/* Description: LIN Description file */
/* System: Superset_EVAC */
/* Variant: Superset */
/* Cluster: LIN15_BCMA */
/* Master: BCMA_LIN15_Ctrl */
/* Generated at: 2026-03-06 10:21 */

LIN_description_file;
LIN_protocol_version = "2.1";
LIN_language_version = "2.1";
LIN_speed = 19.2 kbps;

Channel_name = "";

Nodes {
  Master: BCMA, 5.000 ms, 0.500 ms;
  Slaves: ALM, ALM2, ALM3, ALM4, ALM5, ALM6, ALM7, ALM8, Virtual_EVAC, WCCM;
}

Signals {
  AmbLightBlue1: 8, 0, BCMA, ALM, ALM2, ALM3, ALM4, ALM5, ALM6, ALM7, ALM8;
  AmbLightBlue2: 8, 0, BCMA, ALM, ALM2, ALM3, ALM4, ALM5, ALM6, ALM7, ALM8;
  AmbLightBlue3: 8, 0, BCMA, ALM, ALM2, ALM3, ALM4, ALM5, ALM6, ALM7, ALM8;
  AmbLightBlue4: 8, 0, BCMA, ALM, ALM2, ALM3, ALM4, ALM5, ALM6, ALM7, ALM8;
  AmbLightBlue5: 8, 0, BCMA, ALM, ALM2, ALM3, ALM4, ALM5, ALM6, ALM7, ALM8;
  AmbLIghtFade1: 8, 0, BCMA, ALM, ALM2, ALM3, ALM4, ALM5, ALM6, ALM7, ALM8;
  AmbLIghtFade2: 8, 0, BCMA, ALM, ALM2, ALM3, ALM4, ALM5, ALM6, ALM7, ALM8;
  AmbLIghtFade3: 8, 0, BCMA, ALM, ALM2, ALM3, ALM4, ALM5, ALM6, ALM7, ALM8;
  AmbLIghtFade4: 8, 0, BCMA, ALM, ALM2, ALM3, ALM4, ALM5, ALM6, ALM7, ALM8;
  AmbLIghtFade5: 8, 0, BCMA, ALM, ALM2, ALM3, ALM4, ALM5, ALM6, ALM7, ALM8;
  AmbLightGreen1: 8, 0, BCMA, ALM, ALM2, ALM3, ALM4, ALM5, ALM6, ALM7, ALM8;
  AmbLightGreen2: 8, 0, BCMA, ALM, ALM2, ALM3, ALM4, ALM5, ALM6, ALM7, ALM8;
  AmbLightGreen3: 8, 0, BCMA, ALM, ALM2, ALM3, ALM4, ALM5, ALM6, ALM7, ALM8;
  AmbLightGreen4: 8, 0, BCMA, ALM, ALM2, ALM3, ALM4, ALM5, ALM6, ALM7, ALM8;
  AmbLightGreen5: 8, 0, BCMA, ALM, ALM2, ALM3, ALM4, ALM5, ALM6, ALM7, ALM8;
  AmbLightIntensity1: 6, 0, BCMA, ALM, ALM2, ALM3, ALM4, ALM5, ALM6, ALM7, ALM8;
  AmbLightIntensity2: 6, 0, BCMA, ALM, ALM2, ALM3, ALM4, ALM5, ALM6, ALM7, ALM8;
  AmbLightIntensity3: 6, 0, BCMA, ALM, ALM2, ALM3, ALM4, ALM5, ALM6, ALM7, ALM8;
  AmbLightIntensity4: 6, 0, BCMA, ALM, ALM2, ALM3, ALM4, ALM5, ALM6, ALM7, ALM8;
  AmbLightIntensity5: 6, 0, BCMA, ALM, ALM2, ALM3, ALM4, ALM5, ALM6, ALM7, ALM8;
  AmbLightRamp1: 8, 0, BCMA, ALM, ALM2, ALM3, ALM4, ALM5, ALM6, ALM7, ALM8;
  AmbLightRamp2: 8, 0, BCMA, ALM, ALM2, ALM3, ALM4, ALM5, ALM6, ALM7, ALM8;
  AmbLightRamp3: 8, 0, BCMA, ALM, ALM2, ALM3, ALM4, ALM5, ALM6, ALM7, ALM8;
  AmbLightRamp4: 8, 0, BCMA, ALM, ALM2, ALM3, ALM4, ALM5, ALM6, ALM7, ALM8;
  AmbLightRamp5: 8, 0, BCMA, ALM, ALM2, ALM3, ALM4, ALM5, ALM6, ALM7, ALM8;
  AmbLightRed1: 8, 0, BCMA, ALM, ALM2, ALM3, ALM4, ALM5, ALM6, ALM7, ALM8;
  AmbLightRed2: 8, 0, BCMA, ALM, ALM2, ALM3, ALM4, ALM5, ALM6, ALM7, ALM8;
  AmbLightRed3: 8, 0, BCMA, ALM, ALM2, ALM3, ALM4, ALM5, ALM6, ALM7, ALM8;
  AmbLightRed4: 8, 0, BCMA, ALM, ALM2, ALM3, ALM4, ALM5, ALM6, ALM7, ALM8;
  AmbLightRed5: 8, 0, BCMA, ALM, ALM2, ALM3, ALM4, ALM5, ALM6, ALM7, ALM8;
  AmbLightSeqfrom1: 8, 0, BCMA, ALM, ALM2, ALM3, ALM4, ALM5, ALM6, ALM7, ALM8;
  AmbLightSeqfrom2: 8, 0, BCMA, ALM, ALM2, ALM3, ALM4, ALM5, ALM6, ALM7, ALM8;
  AmbLightSeqfrom3: 8, 0, BCMA, ALM, ALM2, ALM3, ALM4, ALM5, ALM6, ALM7, ALM8;
  AmbLightSeqfrom4: 8, 0, BCMA, ALM, ALM2, ALM3, ALM4, ALM5, ALM6, ALM7, ALM8;
  AmbLightSeqfrom5: 8, 0, BCMA, ALM, ALM2, ALM3, ALM4, ALM5, ALM6, ALM7, ALM8;
  AmbLightSeqTo1: 8, 0, BCMA, ALM, ALM2, ALM3, ALM4, ALM5, ALM6, ALM7, ALM8;
  AmbLightSeqTo2: 8, 0, BCMA, ALM, ALM2, ALM3, ALM4, ALM5, ALM6, ALM7, ALM8;
  AmbLightSeqTo3: 8, 0, BCMA, ALM, ALM2, ALM3, ALM4, ALM5, ALM6, ALM7, ALM8;
  AmbLightSeqTo4: 8, 0, BCMA, ALM, ALM2, ALM3, ALM4, ALM5, ALM6, ALM7, ALM8;
  AmbLightSeqTo5: 8, 0, BCMA, ALM, ALM2, ALM3, ALM4, ALM5, ALM6, ALM7, ALM8;
  AmbLightUpdate1: 2, 0, BCMA, ALM, ALM2, ALM3, ALM4, ALM5, ALM6, ALM7, ALM8;
  AmbLightUpdate2: 2, 0, BCMA, ALM, ALM2, ALM3, ALM4, ALM5, ALM6, ALM7, ALM8;
  AmbLightUpdate3: 2, 0, BCMA, ALM, ALM2, ALM3, ALM4, ALM5, ALM6, ALM7, ALM8;
  AmbLightUpdate4: 2, 0, BCMA, ALM, ALM2, ALM3, ALM4, ALM5, ALM6, ALM7, ALM8;
  AmbLightUpdate5: 2, 0, BCMA, ALM, ALM2, ALM3, ALM4, ALM5, ALM6, ALM7, ALM8;
  BacklightIntensity: 8, 0, BCMA, WCCM;
  BacklightStatus: 1, 0, BCMA, WCCM;
  DiagMasterReqB0_L15: 8, 0, BCMA, Virtual_EVAC;
  DiagMasterReqB1_L15: 8, 0, BCMA, Virtual_EVAC;
  DiagMasterReqB2_L15: 8, 0, BCMA, Virtual_EVAC;
  DiagMasterReqB3_L15: 8, 0, BCMA, Virtual_EVAC;
  DiagMasterReqB4_L15: 8, 0, BCMA, Virtual_EVAC;
  DiagMasterReqB5_L15: 8, 0, BCMA, Virtual_EVAC;
  DiagMasterReqB6_L15: 8, 0, BCMA, Virtual_EVAC;
  DiagMasterReqB7_L15: 8, 0, BCMA, Virtual_EVAC;
  DiagSlaveRespB0_L15: 8, 0, Virtual_EVAC, BCMA;
  DiagSlaveRespB1_L15: 8, 0, Virtual_EVAC, BCMA;
  DiagSlaveRespB2_L15: 8, 0, Virtual_EVAC, BCMA;
  DiagSlaveRespB3_L15: 8, 0, Virtual_EVAC, BCMA;
  DiagSlaveRespB4_L15: 8, 0, Virtual_EVAC, BCMA;
  DiagSlaveRespB5_L15: 8, 0, Virtual_EVAC, BCMA;
  DiagSlaveRespB6_L15: 8, 0, Virtual_EVAC, BCMA;
  DiagSlaveRespB7_L15: 8, 0, Virtual_EVAC, BCMA;
  ElPowerStatus: 2, 0, BCMA, WCCM;
  LimitedPowerMode: 1, 0, BCMA, WCCM;
  PBBatVolt: 8, 140, BCMA, WCCM;
  PowerMode_LIN: 5, 0, BCMA, WCCM;
  SPBBatVolt: 8, 140, BCMA, WCCM;
  WCCMPartNo: 16, 0, WCCM, BCMA;
  WCCMPartNoBlkNo: 4, 0, WCCM, BCMA;
  WCCMSerialNo: 16, 0, WCCM, BCMA;
  WCCMSerialNoBlkNo: 3, 0, WCCM, BCMA;
  ErrRespALM: 1, 0, ALM, BCMA;
  ErrRespALM2: 1, 0, ALM2, BCMA;
  ErrRespALM3: 1, 0, ALM3, BCMA;
  ErrRespALM4: 1, 0, ALM4, BCMA;
  ErrRespALM5: 1, 0, ALM5, BCMA;
  ErrRespALM6: 1, 0, ALM6, BCMA;
  ErrRespALM7: 1, 0, ALM7, BCMA;
  ErrRespALM8: 1, 0, ALM8, BCMA;
  ErrRespWCCM: 1, 0, WCCM, BCMA;
}

Frames {
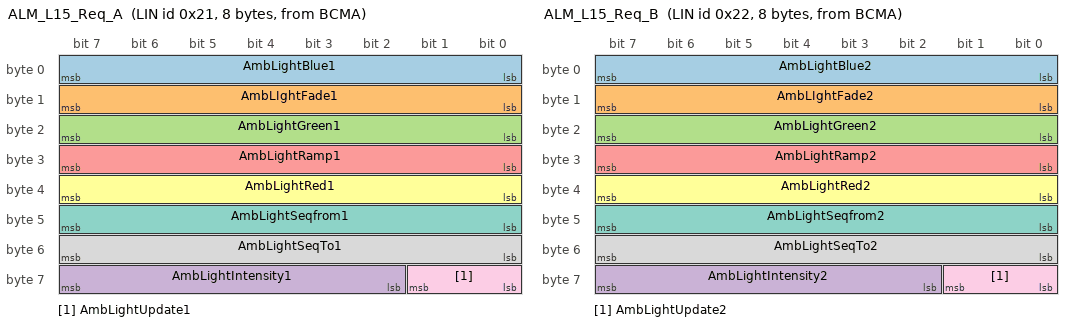
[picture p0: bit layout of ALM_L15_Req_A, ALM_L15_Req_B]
  ALM_L15_Req_A: 0x21, BCMA, 8 {
    AmbLightBlue1, 0;
    AmbLIghtFade1, 8;
    AmbLightGreen1, 16;
    AmbLightIntensity1, 58;
    AmbLightRamp1, 24;
    AmbLightRed1, 32;
    AmbLightSeqfrom1, 40;
    AmbLightSeqTo1, 48;
    AmbLightUpdate1, 56;
  }
  ALM_L15_Req_B: 0x22, BCMA, 8 {
    AmbLightBlue2, 0;
    AmbLIghtFade2, 8;
    AmbLightGreen2, 16;
    AmbLightIntensity2, 58;
    AmbLightRamp2, 24;
    AmbLightRed2, 32;
    AmbLightSeqfrom2, 40;
    AmbLightSeqTo2, 48;
    AmbLightUpdate2, 56;
  }
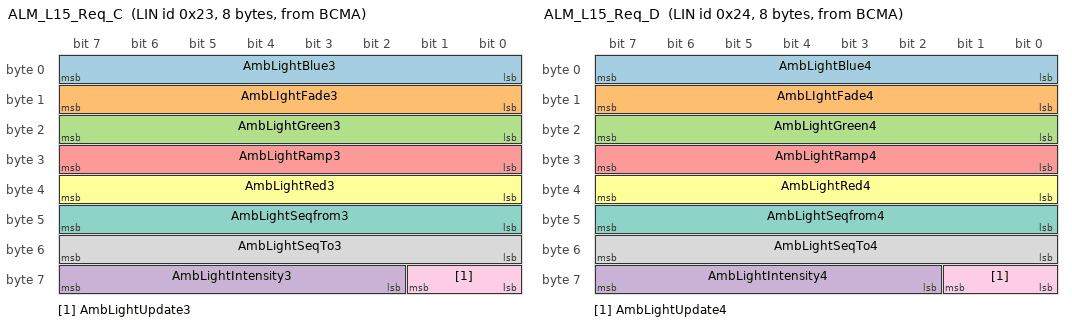
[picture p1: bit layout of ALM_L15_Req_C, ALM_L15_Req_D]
  ALM_L15_Req_C: 0x23, BCMA, 8 {
    AmbLightBlue3, 0;
    AmbLIghtFade3, 8;
    AmbLightGreen3, 16;
    AmbLightIntensity3, 58;
    AmbLightRamp3, 24;
    AmbLightRed3, 32;
    AmbLightSeqfrom3, 40;
    AmbLightSeqTo3, 48;
    AmbLightUpdate3, 56;
  }
  ALM_L15_Req_D: 0x24, BCMA, 8 {
    AmbLightBlue4, 0;
    AmbLIghtFade4, 8;
    AmbLightGreen4, 16;
    AmbLightIntensity4, 58;
    AmbLightRamp4, 24;
    AmbLightRed4, 32;
    AmbLightSeqfrom4, 40;
    AmbLightSeqTo4, 48;
    AmbLightUpdate4, 56;
  }
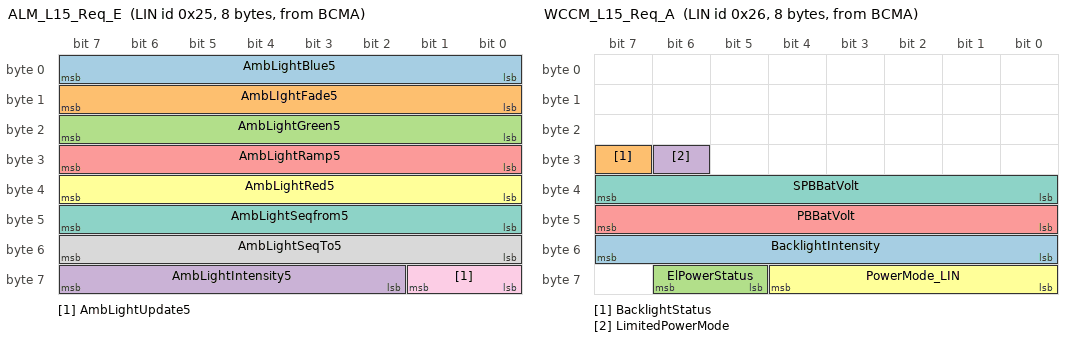
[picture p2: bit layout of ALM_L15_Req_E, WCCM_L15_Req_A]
  ALM_L15_Req_E: 0x25, BCMA, 8 {
    AmbLightBlue5, 0;
    AmbLIghtFade5, 8;
    AmbLightGreen5, 16;
    AmbLightIntensity5, 58;
    AmbLightRamp5, 24;
    AmbLightRed5, 32;
    AmbLightSeqfrom5, 40;
    AmbLightSeqTo5, 48;
    AmbLightUpdate5, 56;
  }
  ALM_L15_Res_A: 0x33, ALM, 1 {
    ErrRespALM, 0;
  }
  ALM_L15_Res_B: 0x34, ALM2, 1 {
    ErrRespALM2, 0;
  }
  ALM_L15_Res_C: 0x35, ALM3, 1 {
    ErrRespALM3, 0;
  }
  ALM_L15_Res_D: 0x36, ALM4, 1 {
    ErrRespALM4, 0;
  }
  ALM_L15_Res_E: 0x37, ALM5, 1 {
    ErrRespALM5, 0;
  }
  ALM_L15_Res_F: 0x38, ALM6, 1 {
    ErrRespALM6, 0;
  }
  ALM_L15_Res_G: 0x39, ALM7, 1 {
    ErrRespALM7, 0;
  }
  ALM_L15_Res_H: 0x3A, ALM8, 1 {
    ErrRespALM8, 0;
  }
  WCCM_L15_Req_A: 0x26, BCMA, 8 {
    BacklightIntensity, 48;
    BacklightStatus, 31;
    ElPowerStatus, 61;
    LimitedPowerMode, 30;
    PBBatVolt, 40;
    PowerMode_LIN, 56;
    SPBBatVolt, 32;
  }
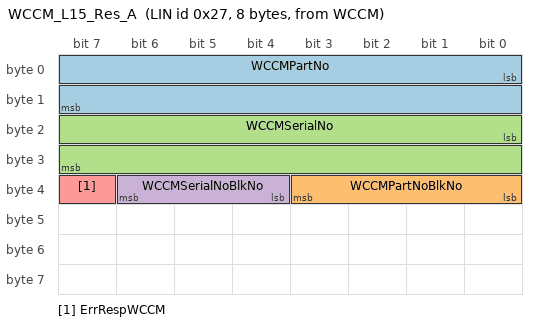
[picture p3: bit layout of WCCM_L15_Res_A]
  WCCM_L15_Res_A: 0x27, WCCM, 8 {
    WCCMPartNo, 0;
    WCCMPartNoBlkNo, 32;
    WCCMSerialNo, 16;
    WCCMSerialNoBlkNo, 36;
    ErrRespWCCM, 39;
  }
}

Node_attributes {
  ALM {
    LIN_protocol = "2.1";
    configured_NAD = 0x01;
    initial_NAD = 0x00;
    product_id = 0x00, 0x00, 0;
    response_error = ErrRespALM;
    configurable_frames {
      ALM_L15_Req_A;
      ALM_L15_Req_B;
      ALM_L15_Req_C;
      ALM_L15_Req_D;
      ALM_L15_Req_E;
      ALM_L15_Res_A;
    }
  }
  ALM2 {
    LIN_protocol = "2.1";
    configured_NAD = 0x01;
    initial_NAD = 0x00;
    product_id = 0x00, 0x00, 0;
    response_error = ErrRespALM2;
    configurable_frames {
      ALM_L15_Req_A;
      ALM_L15_Req_B;
      ALM_L15_Req_C;
      ALM_L15_Req_D;
      ALM_L15_Req_E;
      ALM_L15_Res_B;
    }
  }
  ALM3 {
    LIN_protocol = "2.1";
    configured_NAD = 0x01;
    initial_NAD = 0x00;
    product_id = 0x00, 0x00, 0;
    response_error = ErrRespALM3;
    configurable_frames {
      ALM_L15_Req_A;
      ALM_L15_Req_B;
      ALM_L15_Req_C;
      ALM_L15_Req_D;
      ALM_L15_Req_E;
      ALM_L15_Res_C;
    }
  }
  ALM4 {
    LIN_protocol = "2.1";
    configured_NAD = 0x01;
    initial_NAD = 0x00;
    product_id = 0x00, 0x00, 0;
    response_error = ErrRespALM4;
    configurable_frames {
      ALM_L15_Req_A;
      ALM_L15_Req_B;
      ALM_L15_Req_C;
      ALM_L15_Req_D;
      ALM_L15_Req_E;
      ALM_L15_Res_D;
    }
  }
  ALM5 {
    LIN_protocol = "2.1";
    configured_NAD = 0x01;
    initial_NAD = 0x00;
    product_id = 0x00, 0x00, 0;
    response_error = ErrRespALM5;
    configurable_frames {
      ALM_L15_Req_A;
      ALM_L15_Req_B;
      ALM_L15_Req_C;
      ALM_L15_Req_D;
      ALM_L15_Req_E;
      ALM_L15_Res_E;
    }
  }
  ALM6 {
    LIN_protocol = "2.1";
    configured_NAD = 0x01;
    initial_NAD = 0x00;
    product_id = 0x00, 0x00, 0;
    response_error = ErrRespALM6;
    configurable_frames {
      ALM_L15_Req_A;
      ALM_L15_Req_B;
      ALM_L15_Req_C;
      ALM_L15_Req_D;
      ALM_L15_Req_E;
      ALM_L15_Res_F;
    }
  }
  ALM7 {
    LIN_protocol = "2.1";
    configured_NAD = 0x01;
    initial_NAD = 0x00;
    product_id = 0x00, 0x00, 0;
    response_error = ErrRespALM7;
    configurable_frames {
      ALM_L15_Req_A;
      ALM_L15_Req_B;
      ALM_L15_Req_C;
      ALM_L15_Req_D;
      ALM_L15_Req_E;
      ALM_L15_Res_G;
    }
  }
  ALM8 {
    LIN_protocol = "2.1";
    configured_NAD = 0x01;
    initial_NAD = 0x00;
    product_id = 0x00, 0x00, 0;
    response_error = ErrRespALM8;
    configurable_frames {
      ALM_L15_Req_A;
      ALM_L15_Req_B;
      ALM_L15_Req_C;
      ALM_L15_Req_D;
      ALM_L15_Req_E;
      ALM_L15_Res_H;
    }
  }
  Virtual_EVAC {
    LIN_protocol = "1.3";
    configured_NAD = 0x00;
  }
  WCCM {
    LIN_protocol = "2.1";
    configured_NAD = 0x02;
    initial_NAD = 0x02;
    product_id = 0x00, 0x00, 0;
    response_error = ErrRespWCCM;
    configurable_frames {
      WCCM_L15_Req_A;
      WCCM_L15_Res_A;
    }
  }
}

Schedule_tables {
  DiagRequest_L15 {
    MasterReq delay 10.000 ms;
  }
  DiagRequestResponse_L15 {
    MasterReq delay 10.000 ms;
    SlaveResp delay 10.000 ms;
  }
  DiagResponse_L15 {
    SlaveResp delay 10.000 ms;
  }
  L5_AutoAdr_CCF_0x10_11 {
    FreeFormat {
    0x7F, 0x06, 0xB5, 0xFF, 0x7F, 0x01, 0x02, 0xFF
          } delay 50.000 ms;
    FreeFormat {
    0x7F, 0x06, 0xB5, 0xFF, 0x7F, 0x02, 0x02, 0x34
          } delay 20.000 ms;
    FreeFormat {
    0x7F, 0x06, 0xB5, 0xFF, 0x7F, 0x02, 0x02, 0x2E
          } delay 20.000 ms;
    FreeFormat {
    0x7F, 0x06, 0xB5, 0xFF, 0x7F, 0x02, 0x02, 0x2F
          } delay 20.000 ms;
    FreeFormat {
    0x7F, 0x06, 0xB5, 0xFF, 0x7F, 0x02, 0x02, 0x0E
          } delay 20.000 ms;
    FreeFormat {
    0x7F, 0x06, 0xB5, 0xFF, 0x7F, 0x02, 0x02, 0x10
          } delay 20.000 ms;
    FreeFormat {
    0x7F, 0x06, 0xB5, 0xFF, 0x7F, 0x02, 0x02, 0x0F
          } delay 20.000 ms;
    FreeFormat {
    0x7F, 0x06, 0xB5, 0xFF, 0x7F, 0x02, 0x02, 0x0D
          } delay 20.000 ms;
    FreeFormat {
    0x7F, 0x06, 0xB5, 0xFF, 0x7F, 0x03, 0x02, 0xFF
          } delay 20.000 ms;
    FreeFormat {
    0x7F, 0x06, 0xB5, 0xFF, 0x7F, 0x04, 0x02, 0xFF
          } delay 20.000 ms;
    FreeFormat {
    0x34, 0x06, 0xB7, 0x00, 0x61, 0xE2, 0xA3, 0x64
          } delay 10.000 ms;
    SlaveResp delay 10.000 ms;
    FreeFormat {
    0x34, 0x06, 0xB7, 0x04, 0x25, 0x73, 0xFF, 0xFF
          } delay 10.000 ms;
    SlaveResp delay 10.000 ms;
    FreeFormat {
    0x34, 0x01, 0xB6, 0xFF, 0xFF, 0xFF, 0xFF, 0xFF
          } delay 10.000 ms;
    SlaveResp delay 10.000 ms;
    FreeFormat {
    0x2E, 0x06, 0xB7, 0x00, 0x61, 0xE2, 0xA3, 0x64
          } delay 10.000 ms;
    SlaveResp delay 10.000 ms;
    FreeFormat {
    0x2E, 0x06, 0xB7, 0x04, 0x25, 0xB4, 0xFF, 0xFF
          } delay 10.000 ms;
    SlaveResp delay 10.000 ms;
    FreeFormat {
    0x2E, 0x01, 0xB6, 0xFF, 0xFF, 0xFF, 0xFF, 0xFF
          } delay 10.000 ms;
    SlaveResp delay 10.000 ms;
    FreeFormat {
    0x2F, 0x06, 0xB7, 0x00, 0x61, 0xE2, 0xA3, 0x64
          } delay 10.000 ms;
    SlaveResp delay 10.000 ms;
    FreeFormat {
    0x2F, 0x06, 0xB7, 0x04, 0x25, 0xF5, 0xFF, 0xFF
          } delay 10.000 ms;
    SlaveResp delay 10.000 ms;
    FreeFormat {
    0x2F, 0x01, 0xB6, 0xFF, 0xFF, 0xFF, 0xFF, 0xFF
          } delay 10.000 ms;
    SlaveResp delay 10.000 ms;
    FreeFormat {
    0x0E, 0x06, 0xB7, 0x00, 0x61, 0xE2, 0xA3, 0x64
          } delay 10.000 ms;
    SlaveResp delay 10.000 ms;
    FreeFormat {
    0x0E, 0x06, 0xB7, 0x04, 0x25, 0x76, 0xFF, 0xFF
          } delay 10.000 ms;
    SlaveResp delay 10.000 ms;
    FreeFormat {
    0x0E, 0x01, 0xB6, 0xFF, 0xFF, 0xFF, 0xFF, 0xFF
          } delay 10.000 ms;
    SlaveResp delay 10.000 ms;
    FreeFormat {
    0x10, 0x06, 0xB7, 0x00, 0x61, 0xE2, 0xA3, 0x64
          } delay 10.000 ms;
    SlaveResp delay 10.000 ms;
    FreeFormat {
    0x10, 0x06, 0xB7, 0x04, 0x25, 0x37, 0xFF, 0xFF
          } delay 10.000 ms;
    SlaveResp delay 10.000 ms;
    FreeFormat {
    0x10, 0x01, 0xB6, 0xFF, 0xFF, 0xFF, 0xFF, 0xFF
          } delay 10.000 ms;
    SlaveResp delay 10.000 ms;
    FreeFormat {
    0x0F, 0x06, 0xB7, 0x00, 0x61, 0xE2, 0xA3, 0x64
          } delay 10.000 ms;
    SlaveResp delay 10.000 ms;
    FreeFormat {
    0x0F, 0x06, 0xB7, 0x04, 0x25, 0x78, 0xFF, 0xFF
          } delay 10.000 ms;
    SlaveResp delay 10.000 ms;
    FreeFormat {
    0x0F, 0x01, 0xB6, 0xFF, 0xFF, 0xFF, 0xFF, 0xFF
          } delay 10.000 ms;
    SlaveResp delay 10.000 ms;
    FreeFormat {
    0x0D, 0x06, 0xB7, 0x00, 0x61, 0xE2, 0xA3, 0x64
          } delay 10.000 ms;
    SlaveResp delay 10.000 ms;
    FreeFormat {
    0x0D, 0x06, 0xB7, 0x04, 0x25, 0x39, 0xFF, 0xFF
          } delay 10.000 ms;
    SlaveResp delay 10.000 ms;
    FreeFormat {
    0x0D, 0x01, 0xB6, 0xFF, 0xFF, 0xFF, 0xFF, 0xFF
          } delay 10.000 ms;
    SlaveResp delay 10.000 ms;
  }
  L5_AutoAdr_CCF_0x12_18 {
    FreeFormat {
    0x7F, 0x06, 0xB5, 0xFF, 0x7F, 0x01, 0x02, 0xFF
          } delay 50.000 ms;
    FreeFormat {
    0x7F, 0x06, 0xB5, 0xFF, 0x7F, 0x02, 0x02, 0x10
          } delay 20.000 ms;
    FreeFormat {
    0x7F, 0x06, 0xB5, 0xFF, 0x7F, 0x02, 0x02, 0x0F
          } delay 20.000 ms;
    FreeFormat {
    0x7F, 0x06, 0xB5, 0xFF, 0x7F, 0x03, 0x02, 0xFF
          } delay 20.000 ms;
    FreeFormat {
    0x7F, 0x06, 0xB5, 0xFF, 0x7F, 0x04, 0x02, 0xFF
          } delay 20.000 ms;
    FreeFormat {
    0x10, 0x06, 0xB7, 0x00, 0x61, 0xE2, 0xA3, 0x64
          } delay 10.000 ms;
    SlaveResp delay 10.000 ms;
    FreeFormat {
    0x10, 0x06, 0xB7, 0x04, 0x25, 0x37, 0xFF, 0xFF
          } delay 10.000 ms;
    SlaveResp delay 10.000 ms;
    FreeFormat {
    0x10, 0x01, 0xB6, 0xFF, 0xFF, 0xFF, 0xFF, 0xFF
          } delay 10.000 ms;
    SlaveResp delay 10.000 ms;
    FreeFormat {
    0x0F, 0x06, 0xB7, 0x00, 0x61, 0xE2, 0xA3, 0x64
          } delay 10.000 ms;
    SlaveResp delay 10.000 ms;
    FreeFormat {
    0x0F, 0x06, 0xB7, 0x04, 0x25, 0x78, 0xFF, 0xFF
          } delay 10.000 ms;
    SlaveResp delay 10.000 ms;
    FreeFormat {
    0x0F, 0x01, 0xB6, 0xFF, 0xFF, 0xFF, 0xFF, 0xFF
          } delay 10.000 ms;
    SlaveResp delay 10.000 ms;
  }
  L5_AutoAdr_CCF_0x13 {
    FreeFormat {
    0x7F, 0x06, 0xB5, 0xFF, 0x7F, 0x01, 0x02, 0xFF
          } delay 50.000 ms;
    FreeFormat {
    0x7F, 0x06, 0xB5, 0xFF, 0x7F, 0x02, 0x02, 0x2D
          } delay 20.000 ms;
    FreeFormat {
    0x7F, 0x06, 0xB5, 0xFF, 0x7F, 0x02, 0x02, 0x2F
          } delay 20.000 ms;
    FreeFormat {
    0x7F, 0x06, 0xB5, 0xFF, 0x7F, 0x02, 0x02, 0x2E
          } delay 20.000 ms;
    FreeFormat {
    0x7F, 0x06, 0xB5, 0xFF, 0x7F, 0x02, 0x02, 0x0E
          } delay 20.000 ms;
    FreeFormat {
    0x7F, 0x06, 0xB5, 0xFF, 0x7F, 0x02, 0x02, 0x10
          } delay 20.000 ms;
    FreeFormat {
    0x7F, 0x06, 0xB5, 0xFF, 0x7F, 0x02, 0x02, 0x0F
          } delay 20.000 ms;
    FreeFormat {
    0x7F, 0x06, 0xB5, 0xFF, 0x7F, 0x02, 0x02, 0x0D
          } delay 20.000 ms;
    FreeFormat {
    0x7F, 0x06, 0xB5, 0xFF, 0x7F, 0x03, 0x02, 0xFF
          } delay 20.000 ms;
    FreeFormat {
    0x7F, 0x06, 0xB5, 0xFF, 0x7F, 0x04, 0x02, 0xFF
          } delay 20.000 ms;
    FreeFormat {
    0x2D, 0x06, 0xB7, 0x00, 0x61, 0xE2, 0xA3, 0x64
          } delay 10.000 ms;
    SlaveResp delay 10.000 ms;
    FreeFormat {
    0x2D, 0x06, 0xB7, 0x04, 0x25, 0x73, 0xFF, 0xFF
          } delay 10.000 ms;
    SlaveResp delay 10.000 ms;
    FreeFormat {
    0x2D, 0x01, 0xB6, 0xFF, 0xFF, 0xFF, 0xFF, 0xFF
          } delay 10.000 ms;
    SlaveResp delay 10.000 ms;
    FreeFormat {
    0x2F, 0x06, 0xB7, 0x00, 0x61, 0xE2, 0xA3, 0x64
          } delay 10.000 ms;
    SlaveResp delay 10.000 ms;
    FreeFormat {
    0x2F, 0x06, 0xB7, 0x04, 0x25, 0xB4, 0xFF, 0xFF
          } delay 10.000 ms;
    SlaveResp delay 10.000 ms;
    FreeFormat {
    0x2F, 0x01, 0xB6, 0xFF, 0xFF, 0xFF, 0xFF, 0xFF
          } delay 10.000 ms;
    SlaveResp delay 10.000 ms;
    FreeFormat {
    0x2E, 0x06, 0xB7, 0x00, 0x61, 0xE2, 0xA3, 0x64
          } delay 10.000 ms;
    SlaveResp delay 10.000 ms;
    FreeFormat {
    0x2E, 0x06, 0xB7, 0x04, 0x25, 0xF5, 0xFF, 0xFF
          } delay 10.000 ms;
    SlaveResp delay 10.000 ms;
    FreeFormat {
    0x2E, 0x01, 0xB6, 0xFF, 0xFF, 0xFF, 0xFF, 0xFF
          } delay 10.000 ms;
    SlaveResp delay 10.000 ms;
    FreeFormat {
    0x0E, 0x06, 0xB7, 0x00, 0x61, 0xE2, 0xA3, 0x64
          } delay 10.000 ms;
    SlaveResp delay 10.000 ms;
    FreeFormat {
    0x0E, 0x06, 0xB7, 0x04, 0x25, 0x76, 0xFF, 0xFF
          } delay 10.000 ms;
    SlaveResp delay 10.000 ms;
    FreeFormat {
    0x0E, 0x01, 0xB6, 0xFF, 0xFF, 0xFF, 0xFF, 0xFF
          } delay 10.000 ms;
    SlaveResp delay 10.000 ms;
    FreeFormat {
    0x10, 0x06, 0xB7, 0x00, 0x61, 0xE2, 0xA3, 0x64
          } delay 10.000 ms;
    SlaveResp delay 10.000 ms;
    FreeFormat {
    0x10, 0x06, 0xB7, 0x04, 0x25, 0x37, 0xFF, 0xFF
          } delay 10.000 ms;
    SlaveResp delay 10.000 ms;
    FreeFormat {
    0x10, 0x01, 0xB6, 0xFF, 0xFF, 0xFF, 0xFF, 0xFF
          } delay 10.000 ms;
    SlaveResp delay 10.000 ms;
    FreeFormat {
    0x0F, 0x06, 0xB7, 0x00, 0x61, 0xE2, 0xA3, 0x64
          } delay 10.000 ms;
    SlaveResp delay 10.000 ms;
    FreeFormat {
    0x0F, 0x06, 0xB7, 0x04, 0x25, 0x78, 0xFF, 0xFF
          } delay 10.000 ms;
    SlaveResp delay 10.000 ms;
    FreeFormat {
    0x0F, 0x01, 0xB6, 0xFF, 0xFF, 0xFF, 0xFF, 0xFF
          } delay 10.000 ms;
    SlaveResp delay 10.000 ms;
    FreeFormat {
    0x0D, 0x06, 0xB7, 0x00, 0x61, 0xE2, 0xA3, 0x64
          } delay 10.000 ms;
    SlaveResp delay 10.000 ms;
    FreeFormat {
    0x0D, 0x06, 0xB7, 0x04, 0x25, 0x39, 0xFF, 0xFF
          } delay 10.000 ms;
    SlaveResp delay 10.000 ms;
    FreeFormat {
    0x0D, 0x01, 0xB6, 0xFF, 0xFF, 0xFF, 0xFF, 0xFF
          } delay 10.000 ms;
    SlaveResp delay 10.000 ms;
  }
  L5_AutoAdr_CCF_0x14_16 {
    FreeFormat {
    0x7F, 0x06, 0xB5, 0xFF, 0x7F, 0x01, 0x02, 0xFF
          } delay 50.000 ms;
    FreeFormat {
    0x7F, 0x06, 0xB5, 0xFF, 0x7F, 0x02, 0x02, 0x34
          } delay 20.000 ms;
    FreeFormat {
    0x7F, 0x06, 0xB5, 0xFF, 0x7F, 0x02, 0x02, 0x2E
          } delay 20.000 ms;
    FreeFormat {
    0x7F, 0x06, 0xB5, 0xFF, 0x7F, 0x02, 0x02, 0x2F
          } delay 20.000 ms;
    FreeFormat {
    0x7F, 0x06, 0xB5, 0xFF, 0x7F, 0x02, 0x02, 0x0E
          } delay 20.000 ms;
    FreeFormat {
    0x7F, 0x06, 0xB5, 0xFF, 0x7F, 0x02, 0x02, 0x0F
          } delay 20.000 ms;
    FreeFormat {
    0x7F, 0x06, 0xB5, 0xFF, 0x7F, 0x02, 0x02, 0x0D
          } delay 20.000 ms;
    FreeFormat {
    0x7F, 0x06, 0xB5, 0xFF, 0x7F, 0x02, 0x02, 0x10
          } delay 20.000 ms;
    FreeFormat {
    0x7F, 0x06, 0xB5, 0xFF, 0x7F, 0x03, 0x02, 0xFF
          } delay 20.000 ms;
    FreeFormat {
    0x7F, 0x06, 0xB5, 0xFF, 0x7F, 0x04, 0x02, 0xFF
          } delay 20.000 ms;
    FreeFormat {
    0x34, 0x06, 0xB7, 0x00, 0x61, 0xE2, 0xA3, 0x64
          } delay 10.000 ms;
    SlaveResp delay 10.000 ms;
    FreeFormat {
    0x34, 0x06, 0xB7, 0x04, 0x25, 0x73, 0xFF, 0xFF
          } delay 10.000 ms;
    SlaveResp delay 10.000 ms;
    FreeFormat {
    0x34, 0x01, 0xB6, 0xFF, 0xFF, 0xFF, 0xFF, 0xFF
          } delay 10.000 ms;
    SlaveResp delay 10.000 ms;
    FreeFormat {
    0x2E, 0x06, 0xB7, 0x00, 0x61, 0xE2, 0xA3, 0x64
          } delay 10.000 ms;
    SlaveResp delay 10.000 ms;
    FreeFormat {
    0x2E, 0x06, 0xB7, 0x04, 0x25, 0xB4, 0xFF, 0xFF
          } delay 10.000 ms;
    SlaveResp delay 10.000 ms;
    FreeFormat {
    0x2E, 0x01, 0xB6, 0xFF, 0xFF, 0xFF, 0xFF, 0xFF
          } delay 10.000 ms;
    SlaveResp delay 10.000 ms;
    FreeFormat {
    0x2F, 0x06, 0xB7, 0x00, 0x61, 0xE2, 0xA3, 0x64
          } delay 10.000 ms;
    SlaveResp delay 10.000 ms;
    FreeFormat {
    0x2F, 0x06, 0xB7, 0x04, 0x25, 0xF5, 0xFF, 0xFF
          } delay 10.000 ms;
    SlaveResp delay 10.000 ms;
    FreeFormat {
    0x2F, 0x01, 0xB6, 0xFF, 0xFF, 0xFF, 0xFF, 0xFF
          } delay 10.000 ms;
    SlaveResp delay 10.000 ms;
    FreeFormat {
    0x0E, 0x06, 0xB7, 0x00, 0x61, 0xE2, 0xA3, 0x64
          } delay 10.000 ms;
    SlaveResp delay 10.000 ms;
    FreeFormat {
    0x0E, 0x06, 0xB7, 0x04, 0x25, 0x76, 0xFF, 0xFF
          } delay 10.000 ms;
    SlaveResp delay 10.000 ms;
    FreeFormat {
    0x0E, 0x01, 0xB6, 0xFF, 0xFF, 0xFF, 0xFF, 0xFF
          } delay 10.000 ms;
    SlaveResp delay 10.000 ms;
    FreeFormat {
    0x0F, 0x06, 0xB7, 0x00, 0x61, 0xE2, 0xA3, 0x64
          } delay 10.000 ms;
    SlaveResp delay 10.000 ms;
    FreeFormat {
    0x0F, 0x06, 0xB7, 0x04, 0x25, 0x78, 0xFF, 0xFF
          } delay 10.000 ms;
    SlaveResp delay 10.000 ms;
    FreeFormat {
    0x0F, 0x01, 0xB6, 0xFF, 0xFF, 0xFF, 0xFF, 0xFF
          } delay 10.000 ms;
    SlaveResp delay 10.000 ms;
    FreeFormat {
    0x0D, 0x06, 0xB7, 0x00, 0x61, 0xE2, 0xA3, 0x64
          } delay 10.000 ms;
    SlaveResp delay 10.000 ms;
    FreeFormat {
    0x0D, 0x06, 0xB7, 0x04, 0x25, 0x39, 0xFF, 0xFF
          } delay 10.000 ms;
    SlaveResp delay 10.000 ms;
    FreeFormat {
    0x0D, 0x01, 0xB6, 0xFF, 0xFF, 0xFF, 0xFF, 0xFF
          } delay 10.000 ms;
    SlaveResp delay 10.000 ms;
    FreeFormat {
    0x10, 0x06, 0xB7, 0x00, 0x61, 0xE2, 0xA3, 0x64
          } delay 10.000 ms;
    SlaveResp delay 10.000 ms;
    FreeFormat {
    0x10, 0x06, 0xB7, 0x04, 0x25, 0x37, 0xFF, 0xFF
          } delay 10.000 ms;
    SlaveResp delay 10.000 ms;
    FreeFormat {
    0x10, 0x01, 0xB6, 0xFF, 0xFF, 0xFF, 0xFF, 0xFF
          } delay 10.000 ms;
    SlaveResp delay 10.000 ms;
  }
  L5_AutoAdr_CCF_0x15_17 {
    FreeFormat {
    0x7F, 0x06, 0xB5, 0xFF, 0x7F, 0x01, 0x02, 0xFF
          } delay 50.000 ms;
    FreeFormat {
    0x7F, 0x06, 0xB5, 0xFF, 0x7F, 0x02, 0x02, 0x2E
          } delay 20.000 ms;
    FreeFormat {
    0x7F, 0x06, 0xB5, 0xFF, 0x7F, 0x02, 0x02, 0x2F
          } delay 20.000 ms;
    FreeFormat {
    0x7F, 0x06, 0xB5, 0xFF, 0x7F, 0x02, 0x02, 0x0E
          } delay 20.000 ms;
    FreeFormat {
    0x7F, 0x06, 0xB5, 0xFF, 0x7F, 0x02, 0x02, 0x0F
          } delay 20.000 ms;
    FreeFormat {
    0x7F, 0x06, 0xB5, 0xFF, 0x7F, 0x02, 0x02, 0x0D
          } delay 20.000 ms;
    FreeFormat {
    0x7F, 0x06, 0xB5, 0xFF, 0x7F, 0x02, 0x02, 0x10
          } delay 20.000 ms;
    FreeFormat {
    0x7F, 0x06, 0xB5, 0xFF, 0x7F, 0x03, 0x02, 0xFF
          } delay 20.000 ms;
    FreeFormat {
    0x7F, 0x06, 0xB5, 0xFF, 0x7F, 0x04, 0x02, 0xFF
          } delay 20.000 ms;
    FreeFormat {
    0x2E, 0x06, 0xB7, 0x00, 0x61, 0xE2, 0xA3, 0x64
          } delay 10.000 ms;
    SlaveResp delay 10.000 ms;
    FreeFormat {
    0x2E, 0x06, 0xB7, 0x04, 0x25, 0x73, 0xFF, 0xFF
          } delay 10.000 ms;
    SlaveResp delay 10.000 ms;
    FreeFormat {
    0x2E, 0x01, 0xB6, 0xFF, 0xFF, 0xFF, 0xFF, 0xFF
          } delay 10.000 ms;
    SlaveResp delay 10.000 ms;
    FreeFormat {
    0x2F, 0x06, 0xB7, 0x00, 0x61, 0xE2, 0xA3, 0x64
          } delay 10.000 ms;
    SlaveResp delay 10.000 ms;
    FreeFormat {
    0x2F, 0x06, 0xB7, 0x04, 0x25, 0xB4, 0xFF, 0xFF
          } delay 10.000 ms;
    SlaveResp delay 10.000 ms;
    FreeFormat {
    0x2F, 0x01, 0xB6, 0xFF, 0xFF, 0xFF, 0xFF, 0xFF
          } delay 10.000 ms;
    SlaveResp delay 10.000 ms;
    FreeFormat {
    0x0E, 0x06, 0xB7, 0x00, 0x61, 0xE2, 0xA3, 0x64
          } delay 10.000 ms;
    SlaveResp delay 10.000 ms;
    FreeFormat {
    0x0E, 0x06, 0xB7, 0x04, 0x25, 0xF5, 0xFF, 0xFF
          } delay 10.000 ms;
    SlaveResp delay 10.000 ms;
    FreeFormat {
    0x0E, 0x01, 0xB6, 0xFF, 0xFF, 0xFF, 0xFF, 0xFF
          } delay 10.000 ms;
    SlaveResp delay 10.000 ms;
    FreeFormat {
    0x10, 0x06, 0xB7, 0x00, 0x61, 0xE2, 0xA3, 0x64
          } delay 10.000 ms;
    SlaveResp delay 10.000 ms;
    FreeFormat {
    0x10, 0x06, 0xB7, 0x04, 0x25, 0x76, 0xFF, 0xFF
          } delay 10.000 ms;
    SlaveResp delay 10.000 ms;
    FreeFormat {
    0x10, 0x01, 0xB6, 0xFF, 0xFF, 0xFF, 0xFF, 0xFF
          } delay 10.000 ms;
    SlaveResp delay 10.000 ms;
    FreeFormat {
    0x0F, 0x06, 0xB7, 0x00, 0x61, 0xE2, 0xA3, 0x64
          } delay 10.000 ms;
    SlaveResp delay 10.000 ms;
    FreeFormat {
    0x0F, 0x06, 0xB7, 0x04, 0x25, 0x37, 0xFF, 0xFF
          } delay 10.000 ms;
    SlaveResp delay 10.000 ms;
    FreeFormat {
    0x0F, 0x01, 0xB6, 0xFF, 0xFF, 0xFF, 0xFF, 0xFF
          } delay 10.000 ms;
    SlaveResp delay 10.000 ms;
    FreeFormat {
    0x0D, 0x06, 0xB7, 0x00, 0x61, 0xE2, 0xA3, 0x64
          } delay 10.000 ms;
    SlaveResp delay 10.000 ms;
    FreeFormat {
    0x0D, 0x06, 0xB7, 0x04, 0x25, 0x78, 0xFF, 0xFF
          } delay 10.000 ms;
    SlaveResp delay 10.000 ms;
    FreeFormat {
    0x0D, 0x01, 0xB6, 0xFF, 0xFF, 0xFF, 0xFF, 0xFF
          } delay 10.000 ms;
    SlaveResp delay 10.000 ms;
  }
  L5_AutoAdr_CCF_0x19 {
    FreeFormat {
    0x7F, 0x06, 0xB5, 0xFF, 0x7F, 0x01, 0x02, 0xFF
          } delay 50.000 ms;
    FreeFormat {
    0x7F, 0x06, 0xB5, 0xFF, 0x7F, 0x02, 0x02, 0x12
          } delay 20.000 ms;
    FreeFormat {
    0x7F, 0x06, 0xB5, 0xFF, 0x7F, 0x02, 0x02, 0x11
          } delay 20.000 ms;
    FreeFormat {
    0x7F, 0x06, 0xB5, 0xFF, 0x7F, 0x02, 0x02, 0x2F
          } delay 20.000 ms;
    FreeFormat {
    0x7F, 0x06, 0xB5, 0xFF, 0x7F, 0x02, 0x02, 0x2E
          } delay 20.000 ms;
    FreeFormat {
    0x7F, 0x06, 0xB5, 0xFF, 0x7F, 0x02, 0x02, 0x0E
          } delay 20.000 ms;
    FreeFormat {
    0x7F, 0x06, 0xB5, 0xFF, 0x7F, 0x02, 0x02, 0x10
          } delay 20.000 ms;
    FreeFormat {
    0x7F, 0x06, 0xB5, 0xFF, 0x7F, 0x02, 0x02, 0x0D
          } delay 20.000 ms;
    FreeFormat {
    0x7F, 0x06, 0xB5, 0xFF, 0x7F, 0x03, 0x02, 0xFF
          } delay 20.000 ms;
    FreeFormat {
    0x7F, 0x06, 0xB5, 0xFF, 0x7F, 0x04, 0x02, 0xFF
          } delay 20.000 ms;
    FreeFormat {
    0x12, 0x06, 0xB7, 0x00, 0x61, 0xE2, 0xA3, 0x64
          } delay 10.000 ms;
    SlaveResp delay 10.000 ms;
    FreeFormat {
    0x12, 0x06, 0xB7, 0x04, 0x25, 0x73, 0xFF, 0xFF
          } delay 10.000 ms;
    SlaveResp delay 10.000 ms;
    FreeFormat {
    0x12, 0x01, 0xB6, 0xFF, 0xFF, 0xFF, 0xFF, 0xFF
          } delay 10.000 ms;
    SlaveResp delay 10.000 ms;
    FreeFormat {
    0x11, 0x06, 0xB7, 0x00, 0x61, 0xE2, 0xA3, 0x64
          } delay 10.000 ms;
    SlaveResp delay 10.000 ms;
    FreeFormat {
    0x11, 0x06, 0xB7, 0x04, 0x25, 0xB4, 0xFF, 0xFF
          } delay 10.000 ms;
    SlaveResp delay 10.000 ms;
    FreeFormat {
    0x11, 0x01, 0xB6, 0xFF, 0xFF, 0xFF, 0xFF, 0xFF
          } delay 10.000 ms;
    SlaveResp delay 10.000 ms;
    FreeFormat {
    0x2F, 0x06, 0xB7, 0x00, 0x61, 0xE2, 0xA3, 0x64
          } delay 10.000 ms;
    SlaveResp delay 10.000 ms;
    FreeFormat {
    0x2F, 0x06, 0xB7, 0x04, 0x25, 0xF5, 0xFF, 0xFF
          } delay 10.000 ms;
    SlaveResp delay 10.000 ms;
    FreeFormat {
    0x2F, 0x01, 0xB6, 0xFF, 0xFF, 0xFF, 0xFF, 0xFF
          } delay 10.000 ms;
    SlaveResp delay 10.000 ms;
    FreeFormat {
    0x2E, 0x06, 0xB7, 0x00, 0x61, 0xE2, 0xA3, 0x64
          } delay 10.000 ms;
    SlaveResp delay 10.000 ms;
    FreeFormat {
    0x2E, 0x06, 0xB7, 0x04, 0x25, 0x76, 0xFF, 0xFF
          } delay 10.000 ms;
    SlaveResp delay 10.000 ms;
    FreeFormat {
    0x2E, 0x01, 0xB6, 0xFF, 0xFF, 0xFF, 0xFF, 0xFF
          } delay 10.000 ms;
    SlaveResp delay 10.000 ms;
    FreeFormat {
    0x0E, 0x06, 0xB7, 0x00, 0x61, 0xE2, 0xA3, 0x64
          } delay 10.000 ms;
    SlaveResp delay 10.000 ms;
    FreeFormat {
    0x0E, 0x06, 0xB7, 0x04, 0x25, 0x37, 0xFF, 0xFF
          } delay 10.000 ms;
    SlaveResp delay 10.000 ms;
    FreeFormat {
    0x0E, 0x01, 0xB6, 0xFF, 0xFF, 0xFF, 0xFF, 0xFF
          } delay 10.000 ms;
    SlaveResp delay 10.000 ms;
    FreeFormat {
    0x10, 0x06, 0xB7, 0x00, 0x61, 0xE2, 0xA3, 0x64
          } delay 10.000 ms;
    SlaveResp delay 10.000 ms;
    FreeFormat {
    0x10, 0x06, 0xB7, 0x04, 0x25, 0x78, 0xFF, 0xFF
          } delay 10.000 ms;
    SlaveResp delay 10.000 ms;
    FreeFormat {
    0x10, 0x01, 0xB6, 0xFF, 0xFF, 0xFF, 0xFF, 0xFF
          } delay 10.000 ms;
    SlaveResp delay 10.000 ms;
    FreeFormat {
    0x0D, 0x06, 0xB7, 0x00, 0x61, 0xE2, 0xA3, 0x64
          } delay 10.000 ms;
    SlaveResp delay 10.000 ms;
    FreeFormat {
    0x0D, 0x06, 0xB7, 0x04, 0x25, 0x39, 0xFF, 0xFF
          } delay 10.000 ms;
    SlaveResp delay 10.000 ms;
    FreeFormat {
    0x0D, 0x01, 0xB6, 0xFF, 0xFF, 0xFF, 0xFF, 0xFF
          } delay 10.000 ms;
    SlaveResp delay 10.000 ms;
  }
  L5_AutoAdr_CCF_0x20 {
    FreeFormat {
    0x7F, 0x06, 0xB5, 0xFF, 0x7F, 0x01, 0x02, 0xFF
          } delay 50.000 ms;
    FreeFormat {
    0x7F, 0x06, 0xB5, 0xFF, 0x7F, 0x02, 0x02, 0x12
          } delay 20.000 ms;
    FreeFormat {
    0x7F, 0x06, 0xB5, 0xFF, 0x7F, 0x02, 0x02, 0x11
          } delay 20.000 ms;
    FreeFormat {
    0x7F, 0x06, 0xB5, 0xFF, 0x7F, 0x02, 0x02, 0x2F
          } delay 20.000 ms;
    FreeFormat {
    0x7F, 0x06, 0xB5, 0xFF, 0x7F, 0x02, 0x02, 0x2E
          } delay 20.000 ms;
    FreeFormat {
    0x7F, 0x06, 0xB5, 0xFF, 0x7F, 0x02, 0x02, 0x0E
          } delay 20.000 ms;
    FreeFormat {
    0x7F, 0x06, 0xB5, 0xFF, 0x7F, 0x02, 0x02, 0x10
          } delay 20.000 ms;
    FreeFormat {
    0x7F, 0x06, 0xB5, 0xFF, 0x7F, 0x02, 0x02, 0x0D
          } delay 20.000 ms;
    FreeFormat {
    0x7F, 0x06, 0xB5, 0xFF, 0x7F, 0x03, 0x02, 0xFF
          } delay 20.000 ms;
    FreeFormat {
    0x7F, 0x06, 0xB5, 0xFF, 0x7F, 0x04, 0x02, 0xFF
          } delay 20.000 ms;
    FreeFormat {
    0x12, 0x06, 0xB7, 0x00, 0x61, 0xE2, 0xA3, 0x64
          } delay 10.000 ms;
    SlaveResp delay 10.000 ms;
    FreeFormat {
    0x12, 0x06, 0xB7, 0x04, 0x25, 0x73, 0xFF, 0xFF
          } delay 10.000 ms;
    SlaveResp delay 10.000 ms;
    FreeFormat {
    0x12, 0x01, 0xB6, 0xFF, 0xFF, 0xFF, 0xFF, 0xFF
          } delay 10.000 ms;
    SlaveResp delay 10.000 ms;
    FreeFormat {
    0x11, 0x06, 0xB7, 0x00, 0x61, 0xE2, 0xA3, 0x64
          } delay 10.000 ms;
    SlaveResp delay 10.000 ms;
    FreeFormat {
    0x11, 0x06, 0xB7, 0x04, 0x25, 0xB4, 0xFF, 0xFF
          } delay 10.000 ms;
    SlaveResp delay 10.000 ms;
    FreeFormat {
    0x11, 0x01, 0xB6, 0xFF, 0xFF, 0xFF, 0xFF, 0xFF
          } delay 10.000 ms;
    SlaveResp delay 10.000 ms;
    FreeFormat {
    0x2F, 0x06, 0xB7, 0x00, 0x61, 0xE2, 0xA3, 0x64
          } delay 10.000 ms;
    SlaveResp delay 10.000 ms;
    FreeFormat {
    0x2F, 0x06, 0xB7, 0x04, 0x25, 0xF5, 0xFF, 0xFF
          } delay 10.000 ms;
    SlaveResp delay 10.000 ms;
    FreeFormat {
    0x2F, 0x01, 0xB6, 0xFF, 0xFF, 0xFF, 0xFF, 0xFF
          } delay 10.000 ms;
    SlaveResp delay 10.000 ms;
    FreeFormat {
    0x2E, 0x06, 0xB7, 0x00, 0x61, 0xE2, 0xA3, 0x64
          } delay 10.000 ms;
    SlaveResp delay 10.000 ms;
    FreeFormat {
    0x2E, 0x06, 0xB7, 0x04, 0x25, 0x76, 0xFF, 0xFF
          } delay 10.000 ms;
    SlaveResp delay 10.000 ms;
    FreeFormat {
    0x2E, 0x01, 0xB6, 0xFF, 0xFF, 0xFF, 0xFF, 0xFF
          } delay 10.000 ms;
    SlaveResp delay 10.000 ms;
    FreeFormat {
    0x0E, 0x06, 0xB7, 0x00, 0x61, 0xE2, 0xA3, 0x64
          } delay 10.000 ms;
    SlaveResp delay 10.000 ms;
    FreeFormat {
    0x0E, 0x06, 0xB7, 0x04, 0x25, 0x37, 0xFF, 0xFF
          } delay 10.000 ms;
    SlaveResp delay 10.000 ms;
    FreeFormat {
    0x0E, 0x01, 0xB6, 0xFF, 0xFF, 0xFF, 0xFF, 0xFF
          } delay 10.000 ms;
    SlaveResp delay 10.000 ms;
    FreeFormat {
    0x10, 0x06, 0xB7, 0x00, 0x61, 0xE2, 0xA3, 0x64
          } delay 10.000 ms;
    SlaveResp delay 10.000 ms;
    FreeFormat {
    0x10, 0x06, 0xB7, 0x04, 0x25, 0x78, 0xFF, 0xFF
          } delay 10.000 ms;
    SlaveResp delay 10.000 ms;
    FreeFormat {
    0x10, 0x01, 0xB6, 0xFF, 0xFF, 0xFF, 0xFF, 0xFF
          } delay 10.000 ms;
    SlaveResp delay 10.000 ms;
    FreeFormat {
    0x0D, 0x06, 0xB7, 0x00, 0x61, 0xE2, 0xA3, 0x64
          } delay 10.000 ms;
    SlaveResp delay 10.000 ms;
    FreeFormat {
    0x0D, 0x06, 0xB7, 0x04, 0x25, 0x39, 0xFF, 0xFF
          } delay 10.000 ms;
    SlaveResp delay 10.000 ms;
    FreeFormat {
    0x0D, 0x01, 0xB6, 0xFF, 0xFF, 0xFF, 0xFF, 0xFF
          } delay 10.000 ms;
    SlaveResp delay 10.000 ms;
  }
  L5_IntTable_CCF_0x10_11_LHD {
    FreeFormat {
    0x34, 0x06, 0xB2, 0x21, 0x13, 0x00, 0x01, 0x00
          } delay 10.000 ms;
    SlaveResp delay 10.000 ms;
    FreeFormat {
    0x34, 0x03, 0xB4, 0x91, 0xFF, 0xFF, 0xFF, 0xFF
          } delay 30.000 ms;
    FreeFormat {
    0x34, 0x02, 0xB4, 0x96, 0xFF, 0xFF, 0xFF, 0xFF
          } delay 30.000 ms;
    SlaveResp delay 10.000 ms;
    FreeFormat {
    0x34, 0x06, 0xB2, 0x22, 0x13, 0x00, 0x01, 0x00
          } delay 10.000 ms;
    SlaveResp delay 10.000 ms;
    FreeFormat {
    0x2E, 0x06, 0xB2, 0x21, 0x13, 0x00, 0x01, 0x00
          } delay 10.000 ms;
    SlaveResp delay 10.000 ms;
    FreeFormat {
    0x2E, 0x03, 0xB4, 0x91, 0xFF, 0xFF, 0xFF, 0xFF
          } delay 30.000 ms;
    FreeFormat {
    0x2E, 0x02, 0xB4, 0x96, 0xFF, 0xFF, 0xFF, 0xFF
          } delay 30.000 ms;
    SlaveResp delay 10.000 ms;
    FreeFormat {
    0x2E, 0x06, 0xB2, 0x22, 0x13, 0x00, 0x01, 0x00
          } delay 10.000 ms;
    SlaveResp delay 10.000 ms;
    FreeFormat {
    0x2F, 0x06, 0xB2, 0x21, 0x13, 0x00, 0x01, 0x00
          } delay 10.000 ms;
    SlaveResp delay 10.000 ms;
    FreeFormat {
    0x2F, 0x03, 0xB4, 0x91, 0xFF, 0xFF, 0xFF, 0xFF
          } delay 30.000 ms;
    FreeFormat {
    0x2F, 0x02, 0xB4, 0x96, 0xFF, 0xFF, 0xFF, 0xFF
          } delay 30.000 ms;
    SlaveResp delay 10.000 ms;
    FreeFormat {
    0x2F, 0x06, 0xB2, 0x22, 0x13, 0x00, 0x01, 0x00
          } delay 10.000 ms;
    SlaveResp delay 10.000 ms;
    FreeFormat {
    0x0E, 0x06, 0xB2, 0x21, 0x13, 0x00, 0x01, 0x00
          } delay 10.000 ms;
    SlaveResp delay 10.000 ms;
    FreeFormat {
    0x0E, 0x03, 0xB4, 0x91, 0xFF, 0xFF, 0xFF, 0xFF
          } delay 30.000 ms;
    FreeFormat {
    0x0E, 0x02, 0xB4, 0x96, 0xFF, 0xFF, 0xFF, 0xFF
          } delay 30.000 ms;
    SlaveResp delay 10.000 ms;
    FreeFormat {
    0x0E, 0x06, 0xB2, 0x22, 0x13, 0x00, 0x01, 0x00
          } delay 10.000 ms;
    SlaveResp delay 10.000 ms;
    FreeFormat {
    0x10, 0x06, 0xB2, 0x21, 0x13, 0x00, 0x01, 0x00
          } delay 10.000 ms;
    SlaveResp delay 10.000 ms;
    FreeFormat {
    0x10, 0x03, 0xB4, 0x91, 0xFF, 0xFF, 0xFF, 0xFF
          } delay 30.000 ms;
    FreeFormat {
    0x10, 0x02, 0xB4, 0x96, 0xFF, 0xFF, 0xFF, 0xFF
          } delay 30.000 ms;
    SlaveResp delay 10.000 ms;
    FreeFormat {
    0x10, 0x06, 0xB2, 0x22, 0x13, 0x00, 0x01, 0x00
          } delay 10.000 ms;
    SlaveResp delay 10.000 ms;
    FreeFormat {
    0x0F, 0x06, 0xB2, 0x21, 0x13, 0x00, 0x01, 0x00
          } delay 10.000 ms;
    SlaveResp delay 10.000 ms;
    FreeFormat {
    0x0F, 0x03, 0xB4, 0x91, 0x01, 0xFF, 0xFF, 0xFF
          } delay 30.000 ms;
    FreeFormat {
    0x0F, 0x02, 0xB4, 0x96, 0xFF, 0xFF, 0xFF, 0xFF
          } delay 30.000 ms;
    SlaveResp delay 10.000 ms;
    FreeFormat {
    0x0F, 0x06, 0xB2, 0x22, 0x13, 0x00, 0x01, 0x00
          } delay 10.000 ms;
    SlaveResp delay 10.000 ms;
    FreeFormat {
    0x0D, 0x06, 0xB2, 0x21, 0x13, 0x00, 0x01, 0x00
          } delay 10.000 ms;
    SlaveResp delay 10.000 ms;
    FreeFormat {
    0x0D, 0x03, 0xB4, 0x91, 0x01, 0xFF, 0xFF, 0xFF
          } delay 30.000 ms;
    FreeFormat {
    0x0D, 0x02, 0xB4, 0x96, 0xFF, 0xFF, 0xFF, 0xFF
          } delay 30.000 ms;
    SlaveResp delay 10.000 ms;
    FreeFormat {
    0x0D, 0x06, 0xB2, 0x22, 0x13, 0x00, 0x01, 0x00
          } delay 10.000 ms;
    SlaveResp delay 10.000 ms;
  }
  L5_IntTable_CCF_0x10_11_RHD {
    FreeFormat {
    0x34, 0x06, 0xB2, 0x21, 0x13, 0x00, 0x01, 0x00
          } delay 10.000 ms;
    SlaveResp delay 10.000 ms;
    FreeFormat {
    0x34, 0x03, 0xB4, 0x91, 0xFF, 0xFF, 0xFF, 0xFF
          } delay 30.000 ms;
    FreeFormat {
    0x34, 0x02, 0xB4, 0x96, 0xFF, 0xFF, 0xFF, 0xFF
          } delay 30.000 ms;
    SlaveResp delay 10.000 ms;
    FreeFormat {
    0x34, 0x06, 0xB2, 0x22, 0x13, 0x00, 0x01, 0x00
          } delay 10.000 ms;
    SlaveResp delay 10.000 ms;
    FreeFormat {
    0x2E, 0x06, 0xB2, 0x21, 0x13, 0x00, 0x01, 0x00
          } delay 10.000 ms;
    SlaveResp delay 10.000 ms;
    FreeFormat {
    0x2E, 0x03, 0xB4, 0x91, 0xFF, 0xFF, 0xFF, 0xFF
          } delay 30.000 ms;
    FreeFormat {
    0x2E, 0x02, 0xB4, 0x96, 0xFF, 0xFF, 0xFF, 0xFF
          } delay 30.000 ms;
    SlaveResp delay 10.000 ms;
    FreeFormat {
    0x2E, 0x06, 0xB2, 0x22, 0x13, 0x00, 0x01, 0x00
          } delay 10.000 ms;
    SlaveResp delay 10.000 ms;
    FreeFormat {
    0x2F, 0x06, 0xB2, 0x21, 0x13, 0x00, 0x01, 0x00
          } delay 10.000 ms;
    SlaveResp delay 10.000 ms;
    FreeFormat {
    0x2F, 0x03, 0xB4, 0x91, 0xFF, 0xFF, 0xFF, 0xFF
          } delay 30.000 ms;
    FreeFormat {
    0x2F, 0x02, 0xB4, 0x96, 0xFF, 0xFF, 0xFF, 0xFF
          } delay 30.000 ms;
    SlaveResp delay 10.000 ms;
    FreeFormat {
    0x2F, 0x06, 0xB2, 0x22, 0x13, 0x00, 0x01, 0x00
          } delay 10.000 ms;
    SlaveResp delay 10.000 ms;
    FreeFormat {
    0x0E, 0x06, 0xB2, 0x21, 0x13, 0x00, 0x01, 0x00
          } delay 10.000 ms;
    SlaveResp delay 10.000 ms;
    FreeFormat {
    0x0E, 0x03, 0xB4, 0x91, 0xFF, 0xFF, 0xFF, 0xFF
          } delay 30.000 ms;
    FreeFormat {
    0x0E, 0x02, 0xB4, 0x96, 0xFF, 0xFF, 0xFF, 0xFF
          } delay 30.000 ms;
    SlaveResp delay 10.000 ms;
    FreeFormat {
    0x0E, 0x06, 0xB2, 0x22, 0x13, 0x00, 0x01, 0x00
          } delay 10.000 ms;
    SlaveResp delay 10.000 ms;
    FreeFormat {
    0x10, 0x06, 0xB2, 0x21, 0x13, 0x00, 0x01, 0x00
          } delay 10.000 ms;
    SlaveResp delay 10.000 ms;
    FreeFormat {
    0x10, 0x03, 0xB4, 0x91, 0xFF, 0xFF, 0xFF, 0xFF
          } delay 30.000 ms;
    FreeFormat {
    0x10, 0x02, 0xB4, 0x96, 0xFF, 0xFF, 0xFF, 0xFF
          } delay 30.000 ms;
    SlaveResp delay 10.000 ms;
    FreeFormat {
    0x10, 0x06, 0xB2, 0x22, 0x13, 0x00, 0x01, 0x00
          } delay 10.000 ms;
    SlaveResp delay 10.000 ms;
    FreeFormat {
    0x0F, 0x06, 0xB2, 0x21, 0x13, 0x00, 0x01, 0x00
          } delay 10.000 ms;
    SlaveResp delay 10.000 ms;
    FreeFormat {
    0x0F, 0x03, 0xB4, 0x91, 0x01, 0xFF, 0xFF, 0xFF
          } delay 30.000 ms;
    FreeFormat {
    0x0F, 0x02, 0xB4, 0x96, 0xFF, 0xFF, 0xFF, 0xFF
          } delay 30.000 ms;
    SlaveResp delay 10.000 ms;
    FreeFormat {
    0x0F, 0x06, 0xB2, 0x22, 0x13, 0x00, 0x01, 0x00
          } delay 10.000 ms;
    SlaveResp delay 10.000 ms;
    FreeFormat {
    0x0D, 0x06, 0xB2, 0x21, 0x13, 0x00, 0x01, 0x00
          } delay 10.000 ms;
    SlaveResp delay 10.000 ms;
    FreeFormat {
    0x0D, 0x03, 0xB4, 0x91, 0x01, 0xFF, 0xFF, 0xFF
          } delay 30.000 ms;
    FreeFormat {
    0x0D, 0x02, 0xB4, 0x96, 0xFF, 0xFF, 0xFF, 0xFF
          } delay 30.000 ms;
    SlaveResp delay 10.000 ms;
    FreeFormat {
    0x0D, 0x06, 0xB2, 0x22, 0x13, 0x00, 0x01, 0x00
          } delay 10.000 ms;
    SlaveResp delay 10.000 ms;
  }
  L5_IntTable_CCF_0x12_18_LHD {
    FreeFormat {
    0x10, 0x06, 0xB2, 0x21, 0x13, 0x00, 0x01, 0x00
          } delay 10.000 ms;
    SlaveResp delay 10.000 ms;
    FreeFormat {
    0x10, 0x03, 0xB4, 0x91, 0xFF, 0xFF, 0xFF, 0xFF
          } delay 30.000 ms;
    FreeFormat {
    0x10, 0x02, 0xB4, 0x96, 0xFF, 0xFF, 0xFF, 0xFF
          } delay 30.000 ms;
    SlaveResp delay 10.000 ms;
    FreeFormat {
    0x10, 0x06, 0xB2, 0x22, 0x13, 0x00, 0x01, 0x00
          } delay 10.000 ms;
    SlaveResp delay 10.000 ms;
    FreeFormat {
    0x0F, 0x06, 0xB2, 0x21, 0x13, 0x00, 0x01, 0x00
          } delay 10.000 ms;
    SlaveResp delay 10.000 ms;
    FreeFormat {
    0x0F, 0x03, 0xB4, 0x91, 0xFF, 0xFF, 0xFF, 0xFF
          } delay 30.000 ms;
    FreeFormat {
    0x0F, 0x02, 0xB4, 0x96, 0xFF, 0xFF, 0xFF, 0xFF
          } delay 30.000 ms;
    SlaveResp delay 10.000 ms;
    FreeFormat {
    0x0F, 0x06, 0xB2, 0x22, 0x13, 0x00, 0x01, 0x00
          } delay 10.000 ms;
    SlaveResp delay 10.000 ms;
  }
  L5_IntTable_CCF_0x12_18_RHD {
    FreeFormat {
    0x10, 0x06, 0xB2, 0x21, 0x13, 0x00, 0x01, 0x00
          } delay 10.000 ms;
    SlaveResp delay 10.000 ms;
    FreeFormat {
    0x10, 0x03, 0xB4, 0x91, 0xFF, 0xFF, 0xFF, 0xFF
          } delay 30.000 ms;
    FreeFormat {
    0x10, 0x02, 0xB4, 0x96, 0xFF, 0xFF, 0xFF, 0xFF
          } delay 30.000 ms;
    SlaveResp delay 10.000 ms;
    FreeFormat {
    0x10, 0x06, 0xB2, 0x22, 0x13, 0x00, 0x01, 0x00
          } delay 10.000 ms;
    SlaveResp delay 10.000 ms;
    FreeFormat {
    0x0F, 0x06, 0xB2, 0x21, 0x13, 0x00, 0x01, 0x00
          } delay 10.000 ms;
    SlaveResp delay 10.000 ms;
    FreeFormat {
    0x0F, 0x03, 0xB4, 0x91, 0xFF, 0xFF, 0xFF, 0xFF
          } delay 30.000 ms;
    FreeFormat {
    0x0F, 0x02, 0xB4, 0x96, 0xFF, 0xFF, 0xFF, 0xFF
          } delay 30.000 ms;
    SlaveResp delay 10.000 ms;
    FreeFormat {
    0x0F, 0x06, 0xB2, 0x22, 0x13, 0x00, 0x01, 0x00
          } delay 10.000 ms;
    SlaveResp delay 10.000 ms;
  }
  L5_IntTable_CCF_0x13_LHD {
    FreeFormat {
    0x2D, 0x06, 0xB2, 0x21, 0x50, 0x00, 0x24, 0x00
          } delay 10.000 ms;
    SlaveResp delay 10.000 ms;
    FreeFormat {
    0x2D, 0x03, 0xB4, 0x91, 0xFF, 0xFF, 0xFF, 0xFF
          } delay 30.000 ms;
    FreeFormat {
    0x2D, 0x02, 0xB4, 0x96, 0xFF, 0xFF, 0xFF, 0xFF
          } delay 30.000 ms;
    SlaveResp delay 10.000 ms;
    FreeFormat {
    0x2D, 0x06, 0xB2, 0x22, 0x50, 0x00, 0x24, 0x00
          } delay 10.000 ms;
    SlaveResp delay 10.000 ms;
    FreeFormat {
    0x2F, 0x06, 0xB2, 0x21, 0x50, 0x00, 0x24, 0x00
          } delay 10.000 ms;
    SlaveResp delay 10.000 ms;
    FreeFormat {
    0x2F, 0x03, 0xB4, 0x91, 0xFF, 0xFF, 0xFF, 0xFF
          } delay 30.000 ms;
    FreeFormat {
    0x2F, 0x02, 0xB4, 0x96, 0xFF, 0xFF, 0xFF, 0xFF
          } delay 30.000 ms;
    SlaveResp delay 10.000 ms;
    FreeFormat {
    0x2F, 0x06, 0xB2, 0x22, 0x50, 0x00, 0x24, 0x00
          } delay 10.000 ms;
    SlaveResp delay 10.000 ms;
    FreeFormat {
    0x2E, 0x06, 0xB2, 0x21, 0x50, 0x00, 0x24, 0x00
          } delay 10.000 ms;
    SlaveResp delay 10.000 ms;
    FreeFormat {
    0x2E, 0x03, 0xB4, 0x91, 0xFF, 0xFF, 0xFF, 0xFF
          } delay 30.000 ms;
    FreeFormat {
    0x2E, 0x02, 0xB4, 0x96, 0xFF, 0xFF, 0xFF, 0xFF
          } delay 30.000 ms;
    SlaveResp delay 10.000 ms;
    FreeFormat {
    0x2E, 0x06, 0xB2, 0x22, 0x50, 0x00, 0x24, 0x00
          } delay 10.000 ms;
    SlaveResp delay 10.000 ms;
    FreeFormat {
    0x0E, 0x06, 0xB2, 0x21, 0x50, 0x00, 0x24, 0x00
          } delay 10.000 ms;
    SlaveResp delay 10.000 ms;
    FreeFormat {
    0x0E, 0x03, 0xB4, 0x91, 0xFF, 0xFF, 0xFF, 0xFF
          } delay 30.000 ms;
    FreeFormat {
    0x0E, 0x02, 0xB4, 0x96, 0xFF, 0xFF, 0xFF, 0xFF
          } delay 30.000 ms;
    SlaveResp delay 10.000 ms;
    FreeFormat {
    0x0E, 0x06, 0xB2, 0x22, 0x50, 0x00, 0x24, 0x00
          } delay 10.000 ms;
    SlaveResp delay 10.000 ms;
    FreeFormat {
    0x10, 0x06, 0xB2, 0x21, 0x50, 0x00, 0x24, 0x00
          } delay 10.000 ms;
    SlaveResp delay 10.000 ms;
    FreeFormat {
    0x10, 0x03, 0xB4, 0x91, 0xFF, 0xFF, 0xFF, 0xFF
          } delay 30.000 ms;
    FreeFormat {
    0x10, 0x02, 0xB4, 0x96, 0xFF, 0xFF, 0xFF, 0xFF
          } delay 30.000 ms;
    SlaveResp delay 10.000 ms;
    FreeFormat {
    0x10, 0x06, 0xB2, 0x22, 0x50, 0x00, 0x24, 0x00
          } delay 10.000 ms;
    SlaveResp delay 10.000 ms;
    FreeFormat {
    0x0F, 0x06, 0xB2, 0x21, 0x50, 0x00, 0x24, 0x00
          } delay 10.000 ms;
    SlaveResp delay 10.000 ms;
    FreeFormat {
    0x0F, 0x03, 0xB4, 0x91, 0x01, 0xFF, 0xFF, 0xFF
          } delay 30.000 ms;
    FreeFormat {
    0x0F, 0x02, 0xB4, 0x96, 0xFF, 0xFF, 0xFF, 0xFF
          } delay 30.000 ms;
    SlaveResp delay 10.000 ms;
    FreeFormat {
    0x0F, 0x06, 0xB2, 0x22, 0x50, 0x00, 0x24, 0x00
          } delay 10.000 ms;
    SlaveResp delay 10.000 ms;
    FreeFormat {
    0x0D, 0x06, 0xB2, 0x21, 0x50, 0x00, 0x24, 0x00
          } delay 10.000 ms;
    SlaveResp delay 10.000 ms;
    FreeFormat {
    0x0D, 0x03, 0xB4, 0x91, 0x01, 0xFF, 0xFF, 0xFF
          } delay 10.000 ms;
    FreeFormat {
    0x0D, 0x02, 0xB4, 0x96, 0xFF, 0xFF, 0xFF, 0xFF
          } delay 30.000 ms;
    SlaveResp delay 10.000 ms;
    FreeFormat {
    0x0D, 0x06, 0xB2, 0x22, 0x50, 0x00, 0x24, 0x00
          } delay 10.000 ms;
    SlaveResp delay 10.000 ms;
  }
  L5_IntTable_CCF_0x13_RHD {
    FreeFormat {
    0x2D, 0x06, 0xB2, 0x21, 0x50, 0x00, 0x24, 0x00
          } delay 10.000 ms;
    SlaveResp delay 10.000 ms;
    FreeFormat {
    0x2D, 0x03, 0xB4, 0x91, 0xFF, 0xFF, 0xFF, 0xFF
          } delay 30.000 ms;
    FreeFormat {
    0x2D, 0x02, 0xB4, 0x96, 0xFF, 0xFF, 0xFF, 0xFF
          } delay 30.000 ms;
    SlaveResp delay 10.000 ms;
    FreeFormat {
    0x2D, 0x06, 0xB2, 0x22, 0x50, 0x00, 0x24, 0x00
          } delay 10.000 ms;
    SlaveResp delay 10.000 ms;
    FreeFormat {
    0x2F, 0x06, 0xB2, 0x21, 0x50, 0x00, 0x24, 0x00
          } delay 10.000 ms;
    SlaveResp delay 10.000 ms;
    FreeFormat {
    0x2F, 0x03, 0xB4, 0x91, 0xFF, 0xFF, 0xFF, 0xFF
          } delay 30.000 ms;
    FreeFormat {
    0x2F, 0x02, 0xB4, 0x96, 0xFF, 0xFF, 0xFF, 0xFF
          } delay 30.000 ms;
    SlaveResp delay 10.000 ms;
    FreeFormat {
    0x2F, 0x06, 0xB2, 0x22, 0x50, 0x00, 0x24, 0x00
          } delay 10.000 ms;
    SlaveResp delay 10.000 ms;
    FreeFormat {
    0x2E, 0x06, 0xB2, 0x21, 0x50, 0x00, 0x24, 0x00
          } delay 10.000 ms;
    SlaveResp delay 10.000 ms;
    FreeFormat {
    0x2E, 0x03, 0xB4, 0x91, 0xFF, 0xFF, 0xFF, 0xFF
          } delay 30.000 ms;
    FreeFormat {
    0x2E, 0x02, 0xB4, 0x96, 0xFF, 0xFF, 0xFF, 0xFF
          } delay 30.000 ms;
    SlaveResp delay 10.000 ms;
    FreeFormat {
    0x2E, 0x06, 0xB2, 0x22, 0x50, 0x00, 0x24, 0x00
          } delay 10.000 ms;
    SlaveResp delay 10.000 ms;
    FreeFormat {
    0x0E, 0x06, 0xB2, 0x21, 0x50, 0x00, 0x24, 0x00
          } delay 10.000 ms;
    SlaveResp delay 10.000 ms;
    FreeFormat {
    0x0E, 0x03, 0xB4, 0x91, 0x01, 0xFF, 0xFF, 0xFF
          } delay 30.000 ms;
    FreeFormat {
    0x0E, 0x02, 0xB4, 0x96, 0xFF, 0xFF, 0xFF, 0xFF
          } delay 30.000 ms;
    SlaveResp delay 10.000 ms;
    FreeFormat {
    0x0E, 0x06, 0xB2, 0x22, 0x50, 0x00, 0x24, 0x00
          } delay 10.000 ms;
    SlaveResp delay 10.000 ms;
    FreeFormat {
    0x10, 0x06, 0xB2, 0x21, 0x50, 0x00, 0x24, 0x00
          } delay 10.000 ms;
    SlaveResp delay 10.000 ms;
    FreeFormat {
    0x10, 0x03, 0xB4, 0x91, 0x01, 0xFF, 0xFF, 0xFF
          } delay 30.000 ms;
    FreeFormat {
    0x10, 0x02, 0xB4, 0x96, 0xFF, 0xFF, 0xFF, 0xFF
          } delay 30.000 ms;
    SlaveResp delay 10.000 ms;
    FreeFormat {
    0x10, 0x06, 0xB2, 0x22, 0x50, 0x00, 0x24, 0x00
          } delay 10.000 ms;
    SlaveResp delay 10.000 ms;
    FreeFormat {
    0x0F, 0x06, 0xB2, 0x21, 0x50, 0x00, 0x24, 0x00
          } delay 10.000 ms;
    SlaveResp delay 10.000 ms;
    FreeFormat {
    0x0F, 0x03, 0xB4, 0x91, 0x01, 0xFF, 0xFF, 0xFF
          } delay 30.000 ms;
    FreeFormat {
    0x0F, 0x02, 0xB4, 0x96, 0xFF, 0xFF, 0xFF, 0xFF
          } delay 30.000 ms;
    SlaveResp delay 10.000 ms;
    FreeFormat {
    0x0F, 0x06, 0xB2, 0x22, 0x50, 0x00, 0x24, 0x00
          } delay 10.000 ms;
    SlaveResp delay 10.000 ms;
    FreeFormat {
    0x0D, 0x06, 0xB2, 0x21, 0x50, 0x00, 0x24, 0x00
          } delay 10.000 ms;
    SlaveResp delay 10.000 ms;
    FreeFormat {
    0x0D, 0x03, 0xB4, 0x91, 0x01, 0xFF, 0xFF, 0xFF
          } delay 30.000 ms;
    FreeFormat {
    0x0D, 0x02, 0xB4, 0x96, 0xFF, 0xFF, 0xFF, 0xFF
          } delay 30.000 ms;
    SlaveResp delay 10.000 ms;
    FreeFormat {
    0x0D, 0x06, 0xB2, 0x22, 0x50, 0x00, 0x24, 0x00
          } delay 10.000 ms;
    SlaveResp delay 10.000 ms;
  }
  L5_IntTable_CCF_0x14_0x16_LHD {
    FreeFormat {
    0x2E, 0x06, 0xB2, 0x21, 0x13, 0x00, 0x01, 0x00
          } delay 10.000 ms;
    SlaveResp delay 10.000 ms;
    FreeFormat {
    0x2E, 0x03, 0xB4, 0x91, 0xFF, 0xFF, 0xFF, 0xFF
          } delay 30.000 ms;
    FreeFormat {
    0x2E, 0x02, 0xB4, 0x96, 0xFF, 0xFF, 0xFF, 0xFF
          } delay 30.000 ms;
    SlaveResp delay 10.000 ms;
    FreeFormat {
    0x2E, 0x06, 0xB2, 0x22, 0x13, 0x00, 0x01, 0x00
          } delay 10.000 ms;
    SlaveResp delay 10.000 ms;
    FreeFormat {
    0x2F, 0x06, 0xB2, 0x21, 0x13, 0x00, 0x01, 0x00
          } delay 10.000 ms;
    SlaveResp delay 10.000 ms;
    FreeFormat {
    0x2F, 0x03, 0xB4, 0x91, 0xFF, 0xFF, 0xFF, 0xFF
          } delay 30.000 ms;
    FreeFormat {
    0x2F, 0x02, 0xB4, 0x96, 0xFF, 0xFF, 0xFF, 0xFF
          } delay 30.000 ms;
    SlaveResp delay 10.000 ms;
    FreeFormat {
    0x2F, 0x06, 0xB2, 0x22, 0x13, 0x00, 0x01, 0x00
          } delay 10.000 ms;
    SlaveResp delay 10.000 ms;
    FreeFormat {
    0x0E, 0x06, 0xB2, 0x21, 0x13, 0x00, 0x01, 0x00
          } delay 10.000 ms;
    SlaveResp delay 10.000 ms;
    FreeFormat {
    0x0E, 0x03, 0xB4, 0x91, 0xFF, 0xFF, 0xFF, 0xFF
          } delay 30.000 ms;
    FreeFormat {
    0x0E, 0x02, 0xB4, 0x96, 0xFF, 0xFF, 0xFF, 0xFF
          } delay 30.000 ms;
    SlaveResp delay 10.000 ms;
    FreeFormat {
    0x0E, 0x06, 0xB2, 0x22, 0x13, 0x00, 0x01, 0x00
          } delay 10.000 ms;
    SlaveResp delay 10.000 ms;
    FreeFormat {
    0x0F, 0x06, 0xB2, 0x21, 0x13, 0x00, 0x01, 0x00
          } delay 10.000 ms;
    SlaveResp delay 10.000 ms;
    FreeFormat {
    0x0F, 0x03, 0xB4, 0x91, 0x01, 0xFF, 0xFF, 0xFF
          } delay 30.000 ms;
    FreeFormat {
    0x0F, 0x02, 0xB4, 0x96, 0x01, 0xFF, 0xFF, 0xFF
          } delay 30.000 ms;
    SlaveResp delay 10.000 ms;
    FreeFormat {
    0x0F, 0x06, 0xB2, 0x22, 0x13, 0x00, 0x01, 0x00
          } delay 10.000 ms;
    SlaveResp delay 10.000 ms;
    FreeFormat {
    0x0D, 0x06, 0xB2, 0x21, 0x13, 0x00, 0x01, 0x00
          } delay 10.000 ms;
    SlaveResp delay 10.000 ms;
    FreeFormat {
    0x0D, 0x03, 0xB4, 0x91, 0x01, 0xFF, 0xFF, 0xFF
          } delay 30.000 ms;
    FreeFormat {
    0x0D, 0x02, 0xB4, 0x96, 0x01, 0xFF, 0xFF, 0xFF
          } delay 30.000 ms;
    SlaveResp delay 10.000 ms;
    FreeFormat {
    0x0D, 0x06, 0xB2, 0x22, 0x13, 0x00, 0x01, 0x00
          } delay 10.000 ms;
    SlaveResp delay 10.000 ms;
    FreeFormat {
    0x10, 0x06, 0xB2, 0x21, 0x13, 0x00, 0x01, 0x00
          } delay 10.000 ms;
    SlaveResp delay 10.000 ms;
    FreeFormat {
    0x10, 0x03, 0xB4, 0x91, 0xFF, 0xFF, 0xFF, 0xFF
          } delay 30.000 ms;
    FreeFormat {
    0x10, 0x02, 0xB4, 0x96, 0xFF, 0xFF, 0xFF, 0xFF
          } delay 30.000 ms;
    SlaveResp delay 10.000 ms;
    FreeFormat {
    0x10, 0x06, 0xB2, 0x22, 0x13, 0x00, 0x01, 0x00
          } delay 10.000 ms;
    SlaveResp delay 10.000 ms;
  }
  L5_IntTable_CCF_0x14_0x16_RHD {
    FreeFormat {
    0x2E, 0x06, 0xB2, 0x21, 0x13, 0x00, 0x01, 0x00
          } delay 10.000 ms;
    SlaveResp delay 10.000 ms;
    FreeFormat {
    0x2E, 0x03, 0xB4, 0x91, 0xFF, 0xFF, 0xFF, 0xFF
          } delay 30.000 ms;
    FreeFormat {
    0x2E, 0x02, 0xB4, 0x96, 0xFF, 0xFF, 0xFF, 0xFF
          } delay 30.000 ms;
    SlaveResp delay 10.000 ms;
    FreeFormat {
    0x2E, 0x06, 0xB2, 0x22, 0x13, 0x00, 0x01, 0x00
          } delay 10.000 ms;
    SlaveResp delay 10.000 ms;
    FreeFormat {
    0x2F, 0x06, 0xB2, 0x21, 0x13, 0x00, 0x01, 0x00
          } delay 10.000 ms;
    SlaveResp delay 10.000 ms;
    FreeFormat {
    0x2F, 0x03, 0xB4, 0x91, 0xFF, 0xFF, 0xFF, 0xFF
          } delay 30.000 ms;
    FreeFormat {
    0x2F, 0x02, 0xB4, 0x96, 0xFF, 0xFF, 0xFF, 0xFF
          } delay 30.000 ms;
    SlaveResp delay 10.000 ms;
    FreeFormat {
    0x2F, 0x06, 0xB2, 0x22, 0x13, 0x00, 0x01, 0x00
          } delay 10.000 ms;
    SlaveResp delay 10.000 ms;
    FreeFormat {
    0x0E, 0x06, 0xB2, 0x21, 0x13, 0x00, 0x01, 0x00
          } delay 10.000 ms;
    SlaveResp delay 10.000 ms;
    FreeFormat {
    0x0E, 0x03, 0xB4, 0x91, 0xFF, 0xFF, 0xFF, 0xFF
          } delay 30.000 ms;
    FreeFormat {
    0x0E, 0x02, 0xB4, 0x96, 0xFF, 0xFF, 0xFF, 0xFF
          } delay 30.000 ms;
    SlaveResp delay 10.000 ms;
    FreeFormat {
    0x0E, 0x06, 0xB2, 0x22, 0x13, 0x00, 0x01, 0x00
          } delay 10.000 ms;
    SlaveResp delay 10.000 ms;
    FreeFormat {
    0x0F, 0x06, 0xB2, 0x21, 0x13, 0x00, 0x01, 0x00
          } delay 10.000 ms;
    SlaveResp delay 10.000 ms;
    FreeFormat {
    0x0F, 0x03, 0xB4, 0x91, 0x01, 0xFF, 0xFF, 0xFF
          } delay 30.000 ms;
    FreeFormat {
    0x0F, 0x02, 0xB4, 0x96, 0x01, 0xFF, 0xFF, 0xFF
          } delay 30.000 ms;
    SlaveResp delay 10.000 ms;
    FreeFormat {
    0x0F, 0x06, 0xB2, 0x22, 0x13, 0x00, 0x01, 0x00
          } delay 10.000 ms;
    SlaveResp delay 10.000 ms;
    FreeFormat {
    0x0D, 0x06, 0xB2, 0x21, 0x13, 0x00, 0x01, 0x00
          } delay 10.000 ms;
    SlaveResp delay 10.000 ms;
    FreeFormat {
    0x0D, 0x03, 0xB4, 0x91, 0x01, 0xFF, 0xFF, 0xFF
          } delay 30.000 ms;
    FreeFormat {
    0x0D, 0x02, 0xB4, 0x96, 0x01, 0xFF, 0xFF, 0xFF
          } delay 30.000 ms;
    SlaveResp delay 10.000 ms;
    FreeFormat {
    0x0D, 0x06, 0xB2, 0x22, 0x13, 0x00, 0x01, 0x00
          } delay 10.000 ms;
    SlaveResp delay 10.000 ms;
    FreeFormat {
    0x10, 0x06, 0xB2, 0x21, 0x13, 0x00, 0x01, 0x00
          } delay 10.000 ms;
    SlaveResp delay 10.000 ms;
    FreeFormat {
    0x10, 0x03, 0xB4, 0x91, 0xFF, 0xFF, 0xFF, 0xFF
          } delay 30.000 ms;
    FreeFormat {
    0x10, 0x02, 0xB4, 0x96, 0xFF, 0xFF, 0xFF, 0xFF
          } delay 30.000 ms;
    SlaveResp delay 10.000 ms;
    FreeFormat {
    0x10, 0x06, 0xB2, 0x22, 0x13, 0x00, 0x01, 0x00
          } delay 10.000 ms;
    SlaveResp delay 10.000 ms;
  }
  L5_IntTable_CCF_0x15_17_LHD {
    FreeFormat {
    0x2E, 0x06, 0xB2, 0x21, 0x13, 0x00, 0x01, 0x00
          } delay 10.000 ms;
    SlaveResp delay 10.000 ms;
    FreeFormat {
    0x2E, 0x03, 0xB4, 0x91, 0xFF, 0xFF, 0xFF, 0xFF
          } delay 30.000 ms;
    FreeFormat {
    0x2E, 0x02, 0xB4, 0x96, 0xFF, 0xFF, 0xFF, 0xFF
          } delay 30.000 ms;
    SlaveResp delay 10.000 ms;
    FreeFormat {
    0x2E, 0x06, 0xB2, 0x22, 0x13, 0x00, 0x01, 0x00
          } delay 10.000 ms;
    SlaveResp delay 10.000 ms;
    FreeFormat {
    0x2F, 0x06, 0xB2, 0x21, 0x13, 0x00, 0x01, 0x00
          } delay 10.000 ms;
    SlaveResp delay 10.000 ms;
    FreeFormat {
    0x2F, 0x03, 0xB4, 0x91, 0xFF, 0xFF, 0xFF, 0xFF
          } delay 30.000 ms;
    FreeFormat {
    0x2F, 0x02, 0xB4, 0x96, 0xFF, 0xFF, 0xFF, 0xFF
          } delay 30.000 ms;
    SlaveResp delay 10.000 ms;
    FreeFormat {
    0x2F, 0x06, 0xB2, 0x22, 0x13, 0x00, 0x01, 0x00
          } delay 10.000 ms;
    SlaveResp delay 10.000 ms;
    FreeFormat {
    0x0E, 0x06, 0xB2, 0x21, 0x13, 0x00, 0x01, 0x00
          } delay 10.000 ms;
    SlaveResp delay 10.000 ms;
    FreeFormat {
    0x0E, 0x03, 0xB4, 0x91, 0xFF, 0xFF, 0xFF, 0xFF
          } delay 30.000 ms;
    FreeFormat {
    0x0E, 0x02, 0xB4, 0x96, 0xFF, 0xFF, 0xFF, 0xFF
          } delay 30.000 ms;
    SlaveResp delay 10.000 ms;
    FreeFormat {
    0x0E, 0x06, 0xB2, 0x22, 0x13, 0x00, 0x01, 0x00
          } delay 10.000 ms;
    SlaveResp delay 10.000 ms;
    FreeFormat {
    0x10, 0x06, 0xB2, 0x21, 0x13, 0x00, 0x01, 0x00
          } delay 10.000 ms;
    SlaveResp delay 10.000 ms;
    FreeFormat {
    0x10, 0x03, 0xB4, 0x91, 0xFF, 0xFF, 0xFF, 0xFF
          } delay 30.000 ms;
    FreeFormat {
    0x10, 0x02, 0xB4, 0x96, 0xFF, 0xFF, 0xFF, 0xFF
          } delay 30.000 ms;
    SlaveResp delay 10.000 ms;
    FreeFormat {
    0x10, 0x06, 0xB2, 0x22, 0x13, 0x00, 0x01, 0x00
          } delay 10.000 ms;
    SlaveResp delay 10.000 ms;
    FreeFormat {
    0x0F, 0x06, 0xB2, 0x21, 0x13, 0x00, 0x01, 0x00
          } delay 10.000 ms;
    SlaveResp delay 10.000 ms;
    FreeFormat {
    0x0F, 0x03, 0xB4, 0x91, 0x01, 0xFF, 0xFF, 0xFF
          } delay 30.000 ms;
    FreeFormat {
    0x0F, 0x02, 0xB4, 0x96, 0xFF, 0xFF, 0xFF, 0xFF
          } delay 30.000 ms;
    SlaveResp delay 10.000 ms;
    FreeFormat {
    0x0F, 0x06, 0xB2, 0x22, 0x13, 0x00, 0x01, 0x00
          } delay 10.000 ms;
    SlaveResp delay 10.000 ms;
    FreeFormat {
    0x0D, 0x06, 0xB2, 0x21, 0x13, 0x00, 0x01, 0x00
          } delay 10.000 ms;
    SlaveResp delay 10.000 ms;
    FreeFormat {
    0x0D, 0x03, 0xB4, 0x91, 0x01, 0xFF, 0xFF, 0xFF
          } delay 30.000 ms;
    FreeFormat {
    0x0D, 0x02, 0xB4, 0x96, 0xFF, 0xFF, 0xFF, 0xFF
          } delay 30.000 ms;
    SlaveResp delay 10.000 ms;
    FreeFormat {
    0x0D, 0x06, 0xB2, 0x22, 0x13, 0x00, 0x01, 0x00
          } delay 10.000 ms;
    SlaveResp delay 10.000 ms;
  }
  L5_IntTable_CCF_0x15_17_RHD {
    FreeFormat {
    0x2E, 0x06, 0xB2, 0x21, 0x13, 0x00, 0x01, 0x00
          } delay 10.000 ms;
    SlaveResp delay 10.000 ms;
    FreeFormat {
    0x2E, 0x03, 0xB4, 0x91, 0xFF, 0xFF, 0xFF, 0xFF
          } delay 30.000 ms;
    FreeFormat {
    0x2E, 0x02, 0xB4, 0x96, 0xFF, 0xFF, 0xFF, 0xFF
          } delay 30.000 ms;
    SlaveResp delay 10.000 ms;
    FreeFormat {
    0x2E, 0x06, 0xB2, 0x22, 0x13, 0x00, 0x01, 0x00
          } delay 10.000 ms;
    SlaveResp delay 10.000 ms;
    FreeFormat {
    0x2F, 0x06, 0xB2, 0x21, 0x13, 0x00, 0x01, 0x00
          } delay 10.000 ms;
    SlaveResp delay 10.000 ms;
    FreeFormat {
    0x2F, 0x03, 0xB4, 0x91, 0xFF, 0xFF, 0xFF, 0xFF
          } delay 30.000 ms;
    FreeFormat {
    0x2F, 0x02, 0xB4, 0x96, 0xFF, 0xFF, 0xFF, 0xFF
          } delay 30.000 ms;
    SlaveResp delay 10.000 ms;
    FreeFormat {
    0x2F, 0x06, 0xB2, 0x22, 0x13, 0x00, 0x01, 0x00
          } delay 10.000 ms;
    SlaveResp delay 10.000 ms;
    FreeFormat {
    0x0E, 0x06, 0xB2, 0x21, 0x13, 0x00, 0x01, 0x00
          } delay 10.000 ms;
    SlaveResp delay 10.000 ms;
    FreeFormat {
    0x0E, 0x03, 0xB4, 0x91, 0xFF, 0xFF, 0xFF, 0xFF
          } delay 30.000 ms;
    FreeFormat {
    0x0E, 0x02, 0xB4, 0x96, 0xFF, 0xFF, 0xFF, 0xFF
          } delay 30.000 ms;
    SlaveResp delay 10.000 ms;
    FreeFormat {
    0x0E, 0x06, 0xB2, 0x22, 0x13, 0x00, 0x01, 0x00
          } delay 10.000 ms;
    SlaveResp delay 10.000 ms;
    FreeFormat {
    0x10, 0x06, 0xB2, 0x21, 0x13, 0x00, 0x01, 0x00
          } delay 10.000 ms;
    SlaveResp delay 10.000 ms;
    FreeFormat {
    0x10, 0x03, 0xB4, 0x91, 0xFF, 0xFF, 0xFF, 0xFF
          } delay 30.000 ms;
    FreeFormat {
    0x10, 0x02, 0xB4, 0x96, 0xFF, 0xFF, 0xFF, 0xFF
          } delay 30.000 ms;
    SlaveResp delay 10.000 ms;
    FreeFormat {
    0x10, 0x06, 0xB2, 0x22, 0x13, 0x00, 0x01, 0x00
          } delay 10.000 ms;
    SlaveResp delay 10.000 ms;
    FreeFormat {
    0x0F, 0x06, 0xB2, 0x21, 0x13, 0x00, 0x01, 0x00
          } delay 10.000 ms;
    SlaveResp delay 10.000 ms;
    FreeFormat {
    0x0F, 0x03, 0xB4, 0x91, 0x01, 0xFF, 0xFF, 0xFF
          } delay 30.000 ms;
    FreeFormat {
    0x0F, 0x02, 0xB4, 0x96, 0xFF, 0xFF, 0xFF, 0xFF
          } delay 30.000 ms;
    SlaveResp delay 10.000 ms;
    FreeFormat {
    0x0F, 0x06, 0xB2, 0x22, 0x13, 0x00, 0x01, 0x00
          } delay 10.000 ms;
    SlaveResp delay 10.000 ms;
    FreeFormat {
    0x0D, 0x06, 0xB2, 0x21, 0x13, 0x00, 0x01, 0x00
          } delay 10.000 ms;
    SlaveResp delay 10.000 ms;
    FreeFormat {
    0x0D, 0x03, 0xB4, 0x91, 0x01, 0xFF, 0xFF, 0xFF
          } delay 30.000 ms;
    FreeFormat {
    0x0D, 0x02, 0xB4, 0x96, 0xFF, 0xFF, 0xFF, 0xFF
          } delay 30.000 ms;
    SlaveResp delay 10.000 ms;
    FreeFormat {
    0x0D, 0x06, 0xB2, 0x22, 0x13, 0x00, 0x01, 0x00
          } delay 10.000 ms;
    SlaveResp delay 10.000 ms;
  }
  L5_IntTable_CCF_0x19_LHD {
    FreeFormat {
    0x12, 0x06, 0xB2, 0x21, 0x13, 0x00, 0x01, 0x00
          } delay 10.000 ms;
    SlaveResp delay 10.000 ms;
    FreeFormat {
    0x12, 0x03, 0xB4, 0x91, 0xFF, 0xFF, 0xFF, 0xFF
          } delay 30.000 ms;
    FreeFormat {
    0x12, 0x02, 0xB4, 0x96, 0xFF, 0xFF, 0xFF, 0xFF
          } delay 30.000 ms;
    SlaveResp delay 10.000 ms;
    FreeFormat {
    0x12, 0x06, 0xB2, 0x22, 0x13, 0x00, 0x01, 0x00
          } delay 10.000 ms;
    SlaveResp delay 10.000 ms;
    FreeFormat {
    0x11, 0x06, 0xB2, 0x21, 0x13, 0x00, 0x01, 0x00
          } delay 10.000 ms;
    SlaveResp delay 10.000 ms;
    FreeFormat {
    0x11, 0x03, 0xB4, 0x91, 0xFF, 0xFF, 0xFF, 0xFF
          } delay 30.000 ms;
    FreeFormat {
    0x11, 0x02, 0xB4, 0x96, 0xFF, 0xFF, 0xFF, 0xFF
          } delay 30.000 ms;
    SlaveResp delay 10.000 ms;
    FreeFormat {
    0x11, 0x06, 0xB2, 0x22, 0x13, 0x00, 0x01, 0x00
          } delay 10.000 ms;
    SlaveResp delay 10.000 ms;
    FreeFormat {
    0x2F, 0x06, 0xB2, 0x21, 0x13, 0x00, 0x01, 0x00
          } delay 10.000 ms;
    SlaveResp delay 10.000 ms;
    FreeFormat {
    0x2F, 0x03, 0xB4, 0x91, 0xFF, 0xFF, 0xFF, 0xFF
          } delay 30.000 ms;
    FreeFormat {
    0x2F, 0x02, 0xB4, 0x96, 0xFF, 0xFF, 0xFF, 0xFF
          } delay 30.000 ms;
    SlaveResp delay 10.000 ms;
    FreeFormat {
    0x2F, 0x06, 0xB2, 0x22, 0x13, 0x00, 0x01, 0x00
          } delay 10.000 ms;
    SlaveResp delay 10.000 ms;
    FreeFormat {
    0x2E, 0x06, 0xB2, 0x21, 0x13, 0x00, 0x01, 0x00
          } delay 10.000 ms;
    SlaveResp delay 10.000 ms;
    FreeFormat {
    0x2E, 0x03, 0xB4, 0x91, 0xFF, 0xFF, 0xFF, 0xFF
          } delay 30.000 ms;
    FreeFormat {
    0x2E, 0x02, 0xB4, 0x96, 0xFF, 0xFF, 0xFF, 0xFF
          } delay 30.000 ms;
    SlaveResp delay 10.000 ms;
    FreeFormat {
    0x2E, 0x06, 0xB2, 0x22, 0x13, 0x00, 0x01, 0x00
          } delay 10.000 ms;
    SlaveResp delay 10.000 ms;
    FreeFormat {
    0x0E, 0x06, 0xB2, 0x21, 0x13, 0x00, 0x01, 0x00
          } delay 10.000 ms;
    SlaveResp delay 10.000 ms;
    FreeFormat {
    0x0E, 0x03, 0xB4, 0x91, 0xFF, 0xFF, 0xFF, 0xFF
          } delay 30.000 ms;
    FreeFormat {
    0x0E, 0x02, 0xB4, 0x96, 0xFF, 0xFF, 0xFF, 0xFF
          } delay 30.000 ms;
    SlaveResp delay 10.000 ms;
    FreeFormat {
    0x0E, 0x06, 0xB2, 0x22, 0x13, 0x00, 0x01, 0x00
          } delay 10.000 ms;
    SlaveResp delay 10.000 ms;
    FreeFormat {
    0x10, 0x06, 0xB2, 0x21, 0x13, 0x00, 0x01, 0x00
          } delay 10.000 ms;
    SlaveResp delay 10.000 ms;
    FreeFormat {
    0x10, 0x03, 0xB4, 0x91, 0xFF, 0xFF, 0xFF, 0xFF
          } delay 30.000 ms;
    FreeFormat {
    0x10, 0x02, 0xB4, 0x96, 0xFF, 0xFF, 0xFF, 0xFF
          } delay 30.000 ms;
    SlaveResp delay 10.000 ms;
    FreeFormat {
    0x10, 0x06, 0xB2, 0x22, 0x13, 0x00, 0x01, 0x00
          } delay 10.000 ms;
    SlaveResp delay 10.000 ms;
    FreeFormat {
    0x0D, 0x06, 0xB2, 0x21, 0x13, 0x00, 0x01, 0x00
          } delay 10.000 ms;
    SlaveResp delay 10.000 ms;
    FreeFormat {
    0x0D, 0x03, 0xB4, 0x91, 0xFF, 0xFF, 0xFF, 0xFF
          } delay 30.000 ms;
    FreeFormat {
    0x0D, 0x02, 0xB4, 0x96, 0xFF, 0xFF, 0xFF, 0xFF
          } delay 30.000 ms;
    SlaveResp delay 10.000 ms;
    FreeFormat {
    0x0D, 0x06, 0xB2, 0x22, 0x13, 0x00, 0x01, 0x00
          } delay 10.000 ms;
    SlaveResp delay 10.000 ms;
  }
  L5_IntTable_CCF_0x19_RHD {
    FreeFormat {
    0x12, 0x06, 0xB2, 0x21, 0x13, 0x00, 0x01, 0x00
          } delay 10.000 ms;
    SlaveResp delay 10.000 ms;
    FreeFormat {
    0x12, 0x03, 0xB4, 0x91, 0xFF, 0xFF, 0xFF, 0xFF
          } delay 30.000 ms;
    FreeFormat {
    0x12, 0x02, 0xB4, 0x96, 0xFF, 0xFF, 0xFF, 0xFF
          } delay 30.000 ms;
    SlaveResp delay 10.000 ms;
    FreeFormat {
    0x12, 0x06, 0xB2, 0x22, 0x13, 0x00, 0x01, 0x00
          } delay 10.000 ms;
    SlaveResp delay 10.000 ms;
    FreeFormat {
    0x11, 0x06, 0xB2, 0x21, 0x13, 0x00, 0x01, 0x00
          } delay 10.000 ms;
    SlaveResp delay 10.000 ms;
    FreeFormat {
    0x11, 0x03, 0xB4, 0x91, 0xFF, 0xFF, 0xFF, 0xFF
          } delay 30.000 ms;
    FreeFormat {
    0x11, 0x02, 0xB4, 0x96, 0xFF, 0xFF, 0xFF, 0xFF
          } delay 30.000 ms;
    SlaveResp delay 10.000 ms;
    FreeFormat {
    0x11, 0x06, 0xB2, 0x22, 0x13, 0x00, 0x01, 0x00
          } delay 10.000 ms;
    SlaveResp delay 10.000 ms;
    FreeFormat {
    0x2F, 0x06, 0xB2, 0x21, 0x13, 0x00, 0x01, 0x00
          } delay 10.000 ms;
    SlaveResp delay 10.000 ms;
    FreeFormat {
    0x2F, 0x03, 0xB4, 0x91, 0xFF, 0xFF, 0xFF, 0xFF
          } delay 30.000 ms;
    FreeFormat {
    0x2F, 0x02, 0xB4, 0x96, 0xFF, 0xFF, 0xFF, 0xFF
          } delay 30.000 ms;
    SlaveResp delay 10.000 ms;
    FreeFormat {
    0x2F, 0x06, 0xB2, 0x22, 0x13, 0x00, 0x01, 0x00
          } delay 10.000 ms;
    SlaveResp delay 10.000 ms;
    FreeFormat {
    0x2E, 0x06, 0xB2, 0x21, 0x13, 0x00, 0x01, 0x00
          } delay 10.000 ms;
    SlaveResp delay 10.000 ms;
    FreeFormat {
    0x2E, 0x03, 0xB4, 0x91, 0xFF, 0xFF, 0xFF, 0xFF
          } delay 30.000 ms;
    FreeFormat {
    0x2E, 0x02, 0xB4, 0x96, 0xFF, 0xFF, 0xFF, 0xFF
          } delay 30.000 ms;
    SlaveResp delay 10.000 ms;
    FreeFormat {
    0x2E, 0x06, 0xB2, 0x22, 0x13, 0x00, 0x01, 0x00
          } delay 10.000 ms;
    SlaveResp delay 10.000 ms;
    FreeFormat {
    0x0E, 0x06, 0xB2, 0x21, 0x13, 0x00, 0x01, 0x00
          } delay 10.000 ms;
    SlaveResp delay 10.000 ms;
    FreeFormat {
    0x0E, 0x03, 0xB4, 0x91, 0xFF, 0xFF, 0xFF, 0xFF
          } delay 30.000 ms;
    FreeFormat {
    0x0E, 0x02, 0xB4, 0x96, 0xFF, 0xFF, 0xFF, 0xFF
          } delay 30.000 ms;
    SlaveResp delay 10.000 ms;
    FreeFormat {
    0x0E, 0x06, 0xB2, 0x22, 0x13, 0x00, 0x01, 0x00
          } delay 10.000 ms;
    SlaveResp delay 10.000 ms;
    FreeFormat {
    0x10, 0x06, 0xB2, 0x21, 0x13, 0x00, 0x01, 0x00
          } delay 10.000 ms;
    SlaveResp delay 10.000 ms;
    FreeFormat {
    0x10, 0x03, 0xB4, 0x91, 0xFF, 0xFF, 0xFF, 0xFF
          } delay 30.000 ms;
    FreeFormat {
    0x10, 0x02, 0xB4, 0x96, 0xFF, 0xFF, 0xFF, 0xFF
          } delay 30.000 ms;
    SlaveResp delay 10.000 ms;
    FreeFormat {
    0x10, 0x06, 0xB2, 0x22, 0x13, 0x00, 0x01, 0x00
          } delay 10.000 ms;
    SlaveResp delay 10.000 ms;
    FreeFormat {
    0x0D, 0x06, 0xB2, 0x21, 0x13, 0x00, 0x01, 0x00
          } delay 10.000 ms;
    SlaveResp delay 10.000 ms;
    FreeFormat {
    0x0D, 0x03, 0xB4, 0x91, 0xFF, 0xFF, 0xFF, 0xFF
          } delay 30.000 ms;
    FreeFormat {
    0x0D, 0x02, 0xB4, 0x96, 0xFF, 0xFF, 0xFF, 0xFF
          } delay 30.000 ms;
    SlaveResp delay 10.000 ms;
    FreeFormat {
    0x0D, 0x06, 0xB2, 0x22, 0x13, 0x00, 0x01, 0x00
          } delay 10.000 ms;
    SlaveResp delay 10.000 ms;
  }
  L5_IntTable_CCF_0x20_LHD {
    FreeFormat {
    0x12, 0x06, 0xB2, 0x21, 0x13, 0x00, 0x01, 0x00
          } delay 10.000 ms;
    SlaveResp delay 10.000 ms;
    FreeFormat {
    0x12, 0x03, 0xB4, 0x91, 0xFF, 0xFF, 0xFF, 0xFF
          } delay 30.000 ms;
    FreeFormat {
    0x12, 0x02, 0xB4, 0x96, 0xFF, 0xFF, 0xFF, 0xFF
          } delay 30.000 ms;
    SlaveResp delay 10.000 ms;
    FreeFormat {
    0x12, 0x06, 0xB2, 0x22, 0x13, 0x00, 0x01, 0x00
          } delay 10.000 ms;
    SlaveResp delay 10.000 ms;
    FreeFormat {
    0x11, 0x06, 0xB2, 0x21, 0x13, 0x00, 0x01, 0x00
          } delay 10.000 ms;
    SlaveResp delay 10.000 ms;
    FreeFormat {
    0x11, 0x03, 0xB4, 0x91, 0xFF, 0xFF, 0xFF, 0xFF
          } delay 30.000 ms;
    FreeFormat {
    0x11, 0x02, 0xB4, 0x96, 0xFF, 0xFF, 0xFF, 0xFF
          } delay 30.000 ms;
    SlaveResp delay 10.000 ms;
    FreeFormat {
    0x11, 0x06, 0xB2, 0x22, 0x13, 0x00, 0x01, 0x00
          } delay 10.000 ms;
    SlaveResp delay 10.000 ms;
    FreeFormat {
    0x2F, 0x06, 0xB2, 0x21, 0x13, 0x00, 0x01, 0x00
          } delay 10.000 ms;
    SlaveResp delay 10.000 ms;
    FreeFormat {
    0x2F, 0x03, 0xB4, 0x91, 0xFF, 0xFF, 0xFF, 0xFF
          } delay 30.000 ms;
    FreeFormat {
    0x2F, 0x02, 0xB4, 0x96, 0xFF, 0xFF, 0xFF, 0xFF
          } delay 30.000 ms;
    SlaveResp delay 10.000 ms;
    FreeFormat {
    0x2F, 0x06, 0xB2, 0x22, 0x13, 0x00, 0x01, 0x00
          } delay 10.000 ms;
    SlaveResp delay 10.000 ms;
    FreeFormat {
    0x2E, 0x06, 0xB2, 0x21, 0x13, 0x00, 0x01, 0x00
          } delay 10.000 ms;
    SlaveResp delay 10.000 ms;
    FreeFormat {
    0x2E, 0x03, 0xB4, 0x91, 0xFF, 0xFF, 0xFF, 0xFF
          } delay 30.000 ms;
    FreeFormat {
    0x2E, 0x02, 0xB4, 0x96, 0xFF, 0xFF, 0xFF, 0xFF
          } delay 30.000 ms;
    SlaveResp delay 10.000 ms;
    FreeFormat {
    0x2E, 0x06, 0xB2, 0x22, 0x13, 0x00, 0x01, 0x00
          } delay 10.000 ms;
    SlaveResp delay 10.000 ms;
    FreeFormat {
    0x0E, 0x06, 0xB2, 0x21, 0x13, 0x00, 0x01, 0x00
          } delay 10.000 ms;
    SlaveResp delay 10.000 ms;
    FreeFormat {
    0x0E, 0x03, 0xB4, 0x91, 0xFF, 0xFF, 0xFF, 0xFF
          } delay 30.000 ms;
    FreeFormat {
    0x0E, 0x02, 0xB4, 0x96, 0xFF, 0xFF, 0xFF, 0xFF
          } delay 30.000 ms;
    SlaveResp delay 10.000 ms;
    FreeFormat {
    0x0E, 0x06, 0xB2, 0x22, 0x13, 0x00, 0x01, 0x00
          } delay 10.000 ms;
    SlaveResp delay 10.000 ms;
    FreeFormat {
    0x10, 0x06, 0xB2, 0x21, 0x13, 0x00, 0x01, 0x00
          } delay 10.000 ms;
    SlaveResp delay 10.000 ms;
    FreeFormat {
    0x10, 0x03, 0xB4, 0x91, 0xFF, 0xFF, 0xFF, 0xFF
          } delay 30.000 ms;
    FreeFormat {
    0x10, 0x02, 0xB4, 0x96, 0xFF, 0xFF, 0xFF, 0xFF
          } delay 30.000 ms;
    SlaveResp delay 10.000 ms;
    FreeFormat {
    0x10, 0x06, 0xB2, 0x22, 0x13, 0x00, 0x01, 0x00
          } delay 10.000 ms;
    SlaveResp delay 10.000 ms;
    FreeFormat {
    0x0D, 0x06, 0xB2, 0x21, 0x13, 0x00, 0x01, 0x00
          } delay 10.000 ms;
    SlaveResp delay 10.000 ms;
    FreeFormat {
    0x0D, 0x03, 0xB4, 0x91, 0xFF, 0xFF, 0xFF, 0xFF
          } delay 30.000 ms;
    FreeFormat {
    0x0D, 0x02, 0xB4, 0x96, 0xFF, 0xFF, 0xFF, 0xFF
          } delay 30.000 ms;
    SlaveResp delay 10.000 ms;
    FreeFormat {
    0x0D, 0x06, 0xB2, 0x22, 0x13, 0x00, 0x01, 0x00
          } delay 10.000 ms;
    SlaveResp delay 10.000 ms;
  }
  L5_IntTable_CCF_0x20_RHD {
    FreeFormat {
    0x12, 0x06, 0xB2, 0x21, 0x13, 0x00, 0x01, 0x00
          } delay 10.000 ms;
    SlaveResp delay 10.000 ms;
    FreeFormat {
    0x12, 0x03, 0xB4, 0x91, 0xFF, 0xFF, 0xFF, 0xFF
          } delay 30.000 ms;
    FreeFormat {
    0x12, 0x02, 0xB4, 0x96, 0xFF, 0xFF, 0xFF, 0xFF
          } delay 30.000 ms;
    SlaveResp delay 10.000 ms;
    FreeFormat {
    0x12, 0x06, 0xB2, 0x22, 0x13, 0x00, 0x01, 0x00
          } delay 10.000 ms;
    SlaveResp delay 10.000 ms;
    FreeFormat {
    0x11, 0x06, 0xB2, 0x21, 0x13, 0x00, 0x01, 0x00
          } delay 10.000 ms;
    SlaveResp delay 10.000 ms;
    FreeFormat {
    0x11, 0x03, 0xB4, 0x91, 0xFF, 0xFF, 0xFF, 0xFF
          } delay 30.000 ms;
    FreeFormat {
    0x11, 0x02, 0xB4, 0x96, 0xFF, 0xFF, 0xFF, 0xFF
          } delay 30.000 ms;
    SlaveResp delay 10.000 ms;
    FreeFormat {
    0x11, 0x06, 0xB2, 0x22, 0x13, 0x00, 0x01, 0x00
          } delay 10.000 ms;
    SlaveResp delay 10.000 ms;
    FreeFormat {
    0x2F, 0x06, 0xB2, 0x21, 0x13, 0x00, 0x01, 0x00
          } delay 10.000 ms;
    SlaveResp delay 10.000 ms;
    FreeFormat {
    0x2F, 0x03, 0xB4, 0x91, 0xFF, 0xFF, 0xFF, 0xFF
          } delay 30.000 ms;
    FreeFormat {
    0x2F, 0x02, 0xB4, 0x96, 0xFF, 0xFF, 0xFF, 0xFF
          } delay 30.000 ms;
    SlaveResp delay 10.000 ms;
    FreeFormat {
    0x2F, 0x06, 0xB2, 0x22, 0x13, 0x00, 0x01, 0x00
          } delay 10.000 ms;
    SlaveResp delay 10.000 ms;
    FreeFormat {
    0x2E, 0x06, 0xB2, 0x21, 0x13, 0x00, 0x01, 0x00
          } delay 10.000 ms;
    SlaveResp delay 10.000 ms;
    FreeFormat {
    0x2E, 0x03, 0xB4, 0x91, 0xFF, 0xFF, 0xFF, 0xFF
          } delay 30.000 ms;
    FreeFormat {
    0x2E, 0x02, 0xB4, 0x96, 0xFF, 0xFF, 0xFF, 0xFF
          } delay 30.000 ms;
    SlaveResp delay 10.000 ms;
    FreeFormat {
    0x2E, 0x06, 0xB2, 0x22, 0x13, 0x00, 0x01, 0x00
          } delay 10.000 ms;
    SlaveResp delay 10.000 ms;
    FreeFormat {
    0x0E, 0x06, 0xB2, 0x21, 0x13, 0x00, 0x01, 0x00
          } delay 10.000 ms;
    SlaveResp delay 10.000 ms;
    FreeFormat {
    0x0E, 0x03, 0xB4, 0x91, 0xFF, 0xFF, 0xFF, 0xFF
          } delay 30.000 ms;
    FreeFormat {
    0x0E, 0x02, 0xB4, 0x96, 0xFF, 0xFF, 0xFF, 0xFF
          } delay 30.000 ms;
    SlaveResp delay 10.000 ms;
    FreeFormat {
    0x0E, 0x06, 0xB2, 0x22, 0x13, 0x00, 0x01, 0x00
          } delay 10.000 ms;
    SlaveResp delay 10.000 ms;
    FreeFormat {
    0x10, 0x06, 0xB2, 0x21, 0x13, 0x00, 0x01, 0x00
          } delay 10.000 ms;
    SlaveResp delay 10.000 ms;
    FreeFormat {
    0x10, 0x03, 0xB4, 0x91, 0xFF, 0xFF, 0xFF, 0xFF
          } delay 30.000 ms;
    FreeFormat {
    0x10, 0x02, 0xB4, 0x96, 0xFF, 0xFF, 0xFF, 0xFF
          } delay 30.000 ms;
    SlaveResp delay 10.000 ms;
    FreeFormat {
    0x10, 0x06, 0xB2, 0x22, 0x13, 0x00, 0x01, 0x00
          } delay 10.000 ms;
    SlaveResp delay 10.000 ms;
    FreeFormat {
    0x0D, 0x06, 0xB2, 0x21, 0x13, 0x00, 0x01, 0x00
          } delay 10.000 ms;
    SlaveResp delay 10.000 ms;
    FreeFormat {
    0x0D, 0x03, 0xB4, 0x91, 0xFF, 0xFF, 0xFF, 0xFF
          } delay 30.000 ms;
    FreeFormat {
    0x0D, 0x02, 0xB4, 0x96, 0xFF, 0xFF, 0xFF, 0xFF
          } delay 30.000 ms;
    SlaveResp delay 10.000 ms;
    FreeFormat {
    0x0D, 0x06, 0xB2, 0x22, 0x13, 0x00, 0x01, 0x00
          } delay 10.000 ms;
    SlaveResp delay 10.000 ms;
  }
  Normal_L5 {
    ALM_L15_Req_A delay 10.000 ms;
    ALM_L15_Req_B delay 10.000 ms;
    ALM_L15_Req_C delay 10.000 ms;
    ALM_L15_Req_D delay 10.000 ms;
    ALM_L15_Req_E delay 10.000 ms;
    WCCM_L15_Req_A delay 10.000 ms;
    WCCM_L15_Res_A delay 10.000 ms;
  }
}

Signal_encoding_types {
  AmbLightAdress {
    physical_value, 0, 255, 1.0, 0.0, "";
  }
  AmbLightColor256 {
    physical_value, 0, 255, 1.0, 0.0, "Color";
  }
  AmbLightIntensity64 {
    physical_value, 0, 63, 1.0, 0.0, "Intensity %";
  }
  AmbLightRampFade {
    physical_value, 0, 255, 200.0, 0.0, "milliseconds";
  }
  AmbLightUpdate {
    logical_value, 0, "Immediate update";
    logical_value, 1, "Store and don't update";
    logical_value, 2, "Update to the already stored values";
    logical_value, 3, "Discard";
  }
  BacklightIntensity {
    physical_value, 0, 254, 0.3937, 0.0, "Backlight Intensity %";
    logical_value, 255, "Fault condition Present";
  }
  BacklightStatus {
    logical_value, 0, "Backlight is Off";
    logical_value, 1, "Backlight is On";
  }
  ElPowerStatusCoding {
    logical_value, 0, "KeepActive";
    logical_value, 1, "WarningLowBatteryVolt";
    logical_value, 2, "ShutDown";
    logical_value, 3, "NotUsed";
  }
  LimitedPowerModeCoding {
    logical_value, 0, "False";
    logical_value, 1, "True";
  }
  linear_8 {
    physical_value, 0, 255, 1.0, 0.0, "";
  }
  PartNoBlkNoCoding {
    physical_value, 0, 11, 1.0, 0.0, "Block Number";
  }
  PartNoCoding {
    physical_value, 0, 65535, 1.0, 0.0, "ASCII";
  }
  PowerMode {
    logical_value, 0, "KeyOut";
    logical_value, 1, "KeyRecentlyOut";
    logical_value, 2, "KeyApproved_0";
    logical_value, 3, "PostAccessory_0";
    logical_value, 4, "Accessory_1";
    logical_value, 5, "PostIgnition_1";
    logical_value, 6, "IgnitionOn_2";
    logical_value, 7, "Running_2";
    logical_value, 9, "Crank_3";
  }
  SBVoltCoding {
    physical_value, 0, 255, 0.1, 0.0, "V";
  }
  SerialNoBlkNoCoding {
    physical_value, 0, 7, 1.0, 0.0, "Block Number";
  }
  SerialNoCoding {
    physical_value, 0, 65535, 1.0, 0.0, "ASCII";
  }
}

Signal_representation {
  AmbLightAdress : AmbLightSeqfrom1, AmbLightSeqfrom2, AmbLightSeqfrom3, AmbLightSeqfrom4, AmbLightSeqfrom5,
    AmbLightSeqTo1, AmbLightSeqTo2, AmbLightSeqTo3, AmbLightSeqTo4, AmbLightSeqTo5;
  AmbLightColor256 : AmbLightBlue1, AmbLightBlue2, AmbLightBlue3, AmbLightBlue4, AmbLightBlue5, AmbLightGreen1,
    AmbLightGreen2, AmbLightGreen3, AmbLightGreen4, AmbLightGreen5, AmbLightRed1, AmbLightRed2, AmbLightRed3,
    AmbLightRed4, AmbLightRed5;
  AmbLightIntensity64 : AmbLightIntensity1, AmbLightIntensity2, AmbLightIntensity3, AmbLightIntensity4,
    AmbLightIntensity5;
  AmbLightRampFade : AmbLIghtFade1, AmbLIghtFade2, AmbLIghtFade3, AmbLIghtFade4, AmbLIghtFade5, AmbLightRamp1,
    AmbLightRamp2, AmbLightRamp3, AmbLightRamp4, AmbLightRamp5;
  AmbLightUpdate : AmbLightUpdate1, AmbLightUpdate2, AmbLightUpdate3, AmbLightUpdate4, AmbLightUpdate5;
  BacklightIntensity : BacklightIntensity;
  BacklightStatus : BacklightStatus;
  ElPowerStatusCoding : ElPowerStatus;
  LimitedPowerModeCoding : LimitedPowerMode;
  linear_8 : DiagMasterReqB0_L15, DiagMasterReqB1_L15, DiagMasterReqB2_L15, DiagMasterReqB3_L15,
    DiagMasterReqB4_L15, DiagMasterReqB5_L15, DiagMasterReqB6_L15, DiagMasterReqB7_L15, DiagSlaveRespB0_L15,
    DiagSlaveRespB1_L15, DiagSlaveRespB2_L15, DiagSlaveRespB3_L15, DiagSlaveRespB4_L15, DiagSlaveRespB5_L15,
    DiagSlaveRespB6_L15, DiagSlaveRespB7_L15;
  PartNoBlkNoCoding : WCCMPartNoBlkNo;
  PartNoCoding : WCCMPartNo;
  PowerMode : PowerMode_LIN;
  SBVoltCoding : PBBatVolt, SPBBatVolt;
  SerialNoBlkNoCoding : WCCMSerialNoBlkNo;
  SerialNoCoding : WCCMSerialNo;
}
